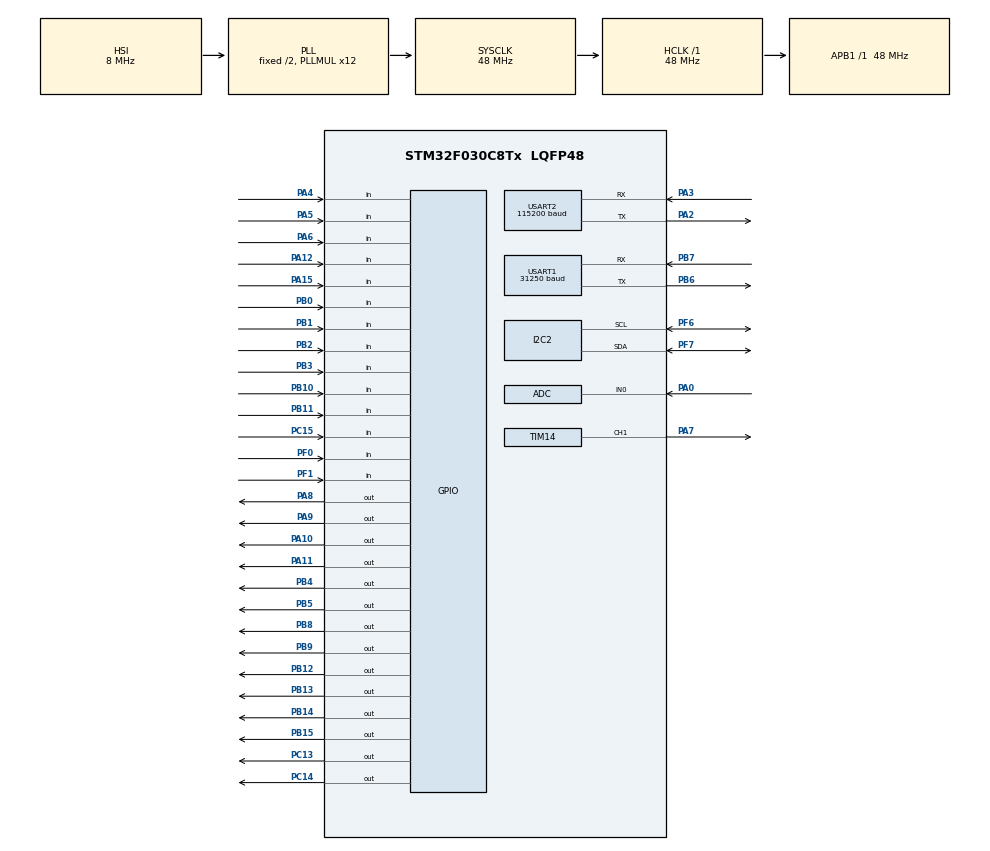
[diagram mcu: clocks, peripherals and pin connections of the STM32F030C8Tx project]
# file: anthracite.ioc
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ADC.SamplingTime=ADC_SAMPLETIME_239CYCLES_5
I2C2.Timing=0x10805D88
Mcu.Family=STM32F0
Mcu.Name=STM32F030C8Tx
Mcu.Package=LQFP48
PA0.Mode=IN0
PA0.Signal=ADC_IN0
PA10.Signal=GPIO_Output
PA11.Signal=GPIO_Output
PA12.Signal=GPIO_Input
PA13.Mode=Serial_Wire
PA13.Signal=SYS_SWDIO
PA14.Mode=Serial_Wire
PA14.Signal=SYS_SWCLK
PA15.GPIO_PuPd=GPIO_PULLUP
PA15.Signal=GPIO_Input
PA2.Mode=Asynchronous
PA2.Signal=USART2_TX
PA3.Mode=Asynchronous
PA3.Signal=USART2_RX
PA4.GPIO_PuPd=GPIO_PULLUP
PA4.Signal=GPIO_Input
PA5.GPIO_PuPd=GPIO_PULLUP
PA5.Signal=GPIO_Input
PA6.GPIO_PuPd=GPIO_PULLUP
PA6.Signal=GPIO_Input
PA7.Signal=S_TIM14_CH1
PA8.Signal=GPIO_Output
PA9.Signal=GPIO_Output
PB0.Signal=GPIO_Input
PB1.Signal=GPIO_Input
PB10.Signal=GPIO_Input
PB11.Signal=GPIO_Input
PB12.Signal=GPIO_Output
PB13.Signal=GPIO_Output
PB14.Signal=GPIO_Output
PB15.Signal=GPIO_Output
PB2.Signal=GPIO_Input
PB3.Signal=GPIO_Input
PB4.Signal=GPIO_Output
PB5.Signal=GPIO_Output
PB6.Mode=Asynchronous
PB6.Signal=USART1_TX
PB7.Mode=Asynchronous
PB7.Signal=USART1_RX
PB8.Signal=GPIO_Output
PB9.Signal=GPIO_Output
PC13.Signal=GPIO_Output
PC14-OSC32_IN.Signal=GPIO_Output
PC15-OSC32_OUT.Signal=GPIO_Input
PF0-OSC_IN.Signal=GPIO_Input
PF1-OSC_OUT.Signal=GPIO_Input
PF6.Mode=I2C
PF6.Signal=I2C2_SCL
PF7.Mode=I2C
PF7.Signal=I2C2_SDA
ProjectManager.HeapSize=0x200
ProjectManager.StackSize=0x400
ProjectManager.TargetToolchain=CMake
RCC.AHBFreq_Value=48000000
RCC.APB1Freq_Value=48000000
RCC.APB1TimFreq_Value=48000000
RCC.HCLKFreq_Value=48000000
RCC.PLLMUL=RCC_PLL_MUL12
RCC.SYSCLKFreq_VALUE=48000000
RCC.SYSCLKSource=RCC_SYSCLKSOURCE_PLLCLK
SH.S_TIM14_CH1.0=TIM14_CH1,PWM Generation1 CH1
TIM14.Channel=TIM_CHANNEL_1
USART1.BaudRate=31250
USART1.VirtualMode-Asynchronous=VM_ASYNC
USART2.BaudRate=115200
USART2.VirtualMode-Asynchronous=VM_ASYNC
VP_ADC_Vref_Input.Mode=IN-Vrefint
VP_TIM14_VS_ClockSourceINT.Mode=Enable_Timer
board=custom

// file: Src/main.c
/* USER CODE BEGIN Header */
/**
  ******************************************************************************
  * @file           : main.c
  * @brief          : Anthracite firmware - main program body
  ******************************************************************************
  * SPDX-FileCopyrightText: 2026 Hayata Yamamoto (Yamamoto Circuit Design)
  * SPDX-License-Identifier: GPL-3.0-or-later
  *
  * Portions generated by STM32CubeMX are
  *   Copyright (c) 2026 STMicroelectronics, licensed under BSD-3-Clause.
  *
  * This program is free software: you can redistribute it and/or modify it
  * under the terms of the GNU General Public License as published by the
  * Free Software Foundation, either version 3 of the License, or (at your
  * option) any later version.
  *
  * This program is distributed in the hope that it will be useful, but
  * WITHOUT ANY WARRANTY; without even the implied warranty of
  * MERCHANTABILITY or FITNESS FOR A PARTICULAR PURPOSE. See the GNU
  * General Public License for more details.
  *
  * You should have received a copy of the GNU General Public License along
  * with this program. If not, see <https://www.gnu.org/licenses/>.
  ******************************************************************************
  */
/* USER CODE END Header */
#include "main.h"

/* USER CODE BEGIN Includes */
#include <stdbool.h>
#include <string.h>
#include <stdio.h>
#include <stdlib.h>
/* USER CODE END Includes */

/* USER CODE BEGIN PTD */
/* VCP debug console: one pin-table row (name lookup, write permission, snapshot output) */
typedef struct {
    GPIO_TypeDef *port;
    uint16_t      pin;
    const char   *name;
    bool          writable;
} dbg_pin_t;
/* USER CODE END PTD */

/* USER CODE BEGIN PD */
/* Firmware version. The boot banner prints it as "anthracite-<FW_VERSION>". Test tools read
   the banner's second word as the firmware ID. The PING reply ("OK PONG v2") is the console protocol
   version and stays independent of this. */
#define FW_VERSION "1.1.0"

/* PL9823-F5 (WS2812-compatible) bit-banged output on PA7.
   PA7 -> R114 -> 74HCT04 (two inverters = non-inverting 5V buffer) -> J105-8 -> top R18 -> D12 DIN */
#define WS_PORT   GPIOA
#define WS_PIN    GPIO_PIN_7
#define WS_HIGH() (WS_PORT->BSRR = WS_PIN)
#define WS_LOW()  (WS_PORT->BSRR = (uint32_t)WS_PIN << 16)
#define NUM_LEDS  1

#define FOOTSW_DEBOUNCE_MS  50
/* Wait after update_mode_pb5() before reading the latch Tip. PB5 (through U107) closes U109 and
   connects the Tip pull-up (+5V -> R127 3k3 -> U109 -> R144 470); the same PB5 also switches U110
   (MIDI-mode Ring source) and D110. Tip must settle before PF0 is sampled. With the on-board C139
   alone the RC is sub-microsecond; with an external cable's capacitance it stays within a few tens
   of microseconds, so 2ms is ample. 2ms also covers a MIDI byte still shifting out of USART1
   (<= 640us with one byte queued) when DIP-SW3 has just gone OFF. */
#define LATCH_PULLUP_SETTLE_MS  2u
/* Latch setting (DIP-SW4 OFF): Tip must hold a new level this long before the effect follows it.
   Measured contact bounce of an external switch on Tip/Ring was about 0.4ms.
   Timing uses the 1ms HAL tick and starts partway through a tick, so the hold actually required
   is 4-5ms. */
#define LATCH_DEBOUNCE_MS       5u
#define IND_SOLID_MS        1000  /* Solid-on time at the start of an indication sequence */
#define IND_BLINK_ON_MS     100
#define IND_BLINK_OFF_MS    100
#define IND_FINAL_OFF_MS    500
#define STARTUP_BLINK_MS    500
#define MIDI_INDICATOR_MS   100   /* PB8/PB9: MIDI activity indicator on-time */
#define LED_FADE_STEP_MS    6     /* PL9823 color fade step interval [ms]; each step closes ~1/3 of the gap */

/* PowerGood ADC (PA0=ADC_IN0) + status LED (PC13)
   Divider R110 10k / R111 3.3k (ratio 3.3/13.3 = 0.24812): 9V in -> 2.23V.
   Warning window: 8.0~12.0V. It encloses the 8.4~11.5V operating range, so the LED does not
   flash inside that range.
   V_DDA is estimated from the VREFINT calibration value to compute the divider voltage [mV];
   PC13 is lit inside the window and blinks at a 0.4s period (50% duty) outside it.
   At 12.0V the divider gives 2.977V, about 0.3V below VDDA (3.28V measured), so the ADC does not saturate. */
#define PGOOD_DIV_LO_MV     1985U  /* Divider voltage for 8.0V (8.0 * 0.24812) */
#define PGOOD_DIV_HI_MV     2977U  /* Divider voltage for 12.0V (12.0 * 0.24812) */
#define PGOOD_POLL_MS       100U   /* ADC sampling interval */
#define PGOOD_BLINK_MS      200U   /* PC13 blink half-period (0.4s period, 50% duty) */
#define ADC_FULL_SCALE      4095U  /* 12bit */
/* VREFINT factory calibration value (taken at VDDA=3.3V). Guarded because bare HAL projects sometimes leave it undefined */
#ifndef VREFINT_CAL_ADDR
#define VREFINT_CAL_ADDR    ((uint16_t *)0x1FFFF7BAU)
#endif
#ifndef VREFINT_CAL_VREF
#define VREFINT_CAL_VREF    3300U    /* mV */
#endif

/* ---- VCP debug console (USART2 PA2/PA3, 115200bps, STLINK-V3 VCP) ---- */
#define DBG_LINE_MAX  64   /* RX line buffer; ample for the longest command ("MSEND"/"MRECV" plus 11 bytes) */
#define DBG_TX_MAX    320  /* TX formatting buffer (a snapshot is ~250 chars, plus the three override fields) */

/* ---- PA8 (Effect) falling-edge delay - pop noise countermeasure ----
   On Effect -> Bypass, PA9 (B-OUT) goes High immediately, but only the PA8 (Effect)
   falling edge is delayed by EFFECT_OFF_DELAY_US. The point is to widen the handover
   overlap between Q8 (bypass side) turning on and Q15 (effect side) turning off
   from 0.6ms to 6.4ms, matching the overlap of the Bypass -> Effect direction.
   Do NOT apply this to the rising edge (Bypass -> Effect): that would shrink the B->E
   overlap from 6.4ms to 0.6ms, making it as hard a splice as E->B, which defeats the purpose.
   Timing uses TIM14 as a 1MHz one-shot (1 count = 1us, max 65.535ms). */
#define EFFECT_OFF_DELAY_US  5800u  /* Default 5.8ms; changeable at runtime with the VCP console EDLY command */
#define EFFECT_OFF_DELAY_MAX 60000u /* Upper bound that still fits the 16-bit TIM14 ARR */

/* MIDI monitor: ring buffer holding USART1 RX/TX bytes tagged with a direction flag.
   Drained by the VCP M command. The size must be a power of two */
#define MIDI_MON_SIZE     128u
#define MIDI_MON_DIR_OUT  0x100u  /* Entry bit8: 0=IN (received), 1=OUT (transmitted) */
#define MIDI_MON_MAX_PER_RESP  40u  /* Max entries per M command (keeps the reply within DBG_TX_MAX) */
/* USER CODE END PD */

ADC_HandleTypeDef hadc;

I2C_HandleTypeDef hi2c2;

TIM_HandleTypeDef htim14;

UART_HandleTypeDef huart1;
UART_HandleTypeDef huart2;

/* USER CODE BEGIN PV */
static bool effect_active = false;

/* PA8 delayed-OFF state. While armed, TIM14 is running and the ISR drives PA8 Low on expiry */
static volatile bool     effect_off_armed    = false;
static volatile uint16_t effect_off_delay_us = EFFECT_OFF_DELAY_US;
static volatile uint16_t effect_off_count    = 0;  /* Number of delayed OFFs executed (reported by EDLY) */

static bool dip_sw1 = false; /* ON(Low)=power-on effect enabled */
static bool dip_sw2 = false; /* ON(Low)=extended bias mode */
static volatile bool dip_sw3 = false; /* ON(Low)=MIDI mode / OFF(High)=latch mode. volatile: the USART1 ISR reads it to gate Thru */
static bool dip_sw4 = false; /* latch mode (OFF) / momentary mode (ON) */

/* Toggle switch inputs (all three have pole = GND and an external +3.3V pull-up).
   Pos1 Low = flipped up / Pos3 Low = flipped down / both High = center.
   The schematic net names match the physical layout. */
static GPIO_PinState prev_latch_tip  = GPIO_PIN_SET; /* PF0 */
static GPIO_PinState prev_latch_ring = GPIO_PIN_SET; /* PF1 */
/* Tip debounce for the latch setting: the level being timed and the HAL tick when it was first seen.
   prev_latch_tip holds the accepted level; latch_tip_cand differs from it while a change is pending. */
static GPIO_PinState latch_tip_cand    = GPIO_PIN_SET;
static uint32_t      latch_tip_cand_ms = 0;
static GPIO_PinState prev_bias_pos1  = GPIO_PIN_SET; /* PB2  */
static GPIO_PinState prev_bias_pos3  = GPIO_PIN_SET; /* PB3  */
static GPIO_PinState prev_resp_pos1  = GPIO_PIN_SET; /* PB0  */
static GPIO_PinState prev_resp_pos3  = GPIO_PIN_SET; /* PB1  */
static GPIO_PinState prev_filt_pos1  = GPIO_PIN_SET; /* PB10 */
static GPIO_PinState prev_filt_pos3  = GPIO_PIN_SET; /* PB11 */
static GPIO_PinState prev_footsw     = GPIO_PIN_SET; /* PA12 */

static volatile uint32_t footsw_debounce_ms = 0;

static uint8_t led_data[NUM_LEDS][3];       /* Current color actually sent to the PL9823 (this is what fades) */
static uint8_t led_target[3] = {0, 0, 0};   /* Target color chosen by update_led(); led_data eases toward it */
static volatile uint32_t led_fade_ms = 0;   /* Countdown to the next fade step (decremented by SysTick) */
static volatile uint8_t led_update_needed = 1;

typedef enum {
    LED_OVERRIDE_NONE = 0,
    LED_OVERRIDE_ORANGE, /* Bias change indication */
    LED_OVERRIDE_GREEN,  /* Input filter change indication */
    LED_OVERRIDE_CYAN,   /* Response change indication */
    LED_OVERRIDE_WHITE,  /* MIDI-Learn store-complete indication */
    LED_OVERRIDE_OFF,    /* forced off (blink gap) */
} led_override_t;
static volatile led_override_t led_override = LED_OVERRIDE_NONE;

typedef enum {
    IND_SEQ_IDLE = 0,
    IND_SEQ_SOLID_1S,
    IND_SEQ_BLINK_OFF,
    IND_SEQ_BLINK_ON,
    IND_SEQ_FINAL_OFF,
} ind_seq_state_t;

typedef struct {
    volatile ind_seq_state_t state;
    volatile uint8_t         blink_remain;
    volatile uint32_t        timer_ms;
    led_override_t           color;
} ind_seq_t;

static ind_seq_t bias_seq   = { IND_SEQ_IDLE, 0, 0, LED_OVERRIDE_ORANGE };
static ind_seq_t filter_seq = { IND_SEQ_IDLE, 0, 0, LED_OVERRIDE_GREEN  };
static ind_seq_t resp_seq   = { IND_SEQ_IDLE, 0, 0, LED_OVERRIDE_CYAN   };
static ind_seq_t learn_seq  = { IND_SEQ_IDLE, 0, 0, LED_OVERRIDE_WHITE  };

static volatile uint32_t startup_blink_ms = 0;
static volatile uint8_t  startup_blink_phase = 0;

/* MIDI IN (USART1, 31250bps) - parses Control Change messages.
   DIP-SW4 OFF: fixed trigger CH12 CC81 / DIP-SW4 ON: the CH/CC stored by MIDI-Learn */
#define TRIG_CH_FIXED  11u    /* CH12 (0-indexed) */
#define TRIG_CC_FIXED  0x51u  /* CC81 */
/* CCs that change the toggle settings over MIDI.
   The channel follows the same rule as on/off control (DIP-SW4 OFF = fixed CH12 / ON = the MIDI-Learn channel).
   value 0 means "revert": clear the MIDI override and follow the physical toggle again.
   value 1-127 is split into four bands (1-31/32-63/64-95/96-127) to select the state. */
#define TOGGLE_CC_INPUT     83u  /* 0=revert / Single / Hum / Wah / All-OFF */
#define TOGGLE_CC_RESPONSE  84u  /* 0=revert / Steep / Medium / Gradual / (N/A) */
#define TOGGLE_CC_BIAS      85u  /* 0=revert / Center / Offset / Skew / X-Skew */
typedef enum { MIDI_IDLE = 0, MIDI_DATA1, MIDI_DATA2 } midi_state_t;
static volatile uint8_t   midi_rx_buf  = 0;
static          midi_state_t midi_state = MIDI_IDLE;
static          uint8_t      midi_status = 0; /* Most recent Channel Voice status byte */
static          uint8_t      midi_cc_num = 0;
/* Received-CC event queue (SPSC: the ISR produces, poll_midi consumes).
   A single-event slot drops CCs that arrive back to back, as in a preset recall, because the
   next one overwrites it before poll_midi runs. A ring buffer serializes them (size = power of two).
   Push only from the USART1 ISR or inside an __disable_irq() section (MRECV injection). */
#define MIDI_EVT_SIZE 16u
typedef struct { uint8_t ch, cc, val; } midi_evt_t;
static volatile midi_evt_t midi_evt_buf[MIDI_EVT_SIZE];
static volatile uint8_t    midi_evt_head = 0;
static volatile uint8_t    midi_evt_tail = 0;

/* MIDI receive health counters (read and cleared with the VCP MSTAT command).
   Observation points added to prove numerically that a burst of CCs loses nothing.
   - midi_rx_err  : USART1 receive errors (ORE/FE/NE) = a proxy for bytes lost on the wire
   - midi_evt_drop: CCs dropped because the event queue was full (proof that poll_midi fell behind)
   - midi_evt_qmax: high-water mark of queue usage (measured headroom against 16)
   - midi_cc_rx   : total CCs that reached midi_process_event() (cross-check against the host)
   All are plain increments without saturation, but uint16 is plenty in practice (CLR before a test). */
static volatile uint16_t midi_rx_err   = 0;
static volatile uint16_t midi_evt_drop = 0;
static volatile uint8_t  midi_evt_qmax = 0;
static volatile uint16_t midi_cc_rx    = 0;

/* MIDI override state for the toggle settings.
   Moving a physical toggle clears the override and returns to reading the switch (done in poll_*_switch).
   While override != NONE, update_*_output() applies it in preference to the physical reading. */
typedef enum {
    FILT_OVR_NONE = 0,   /* follow the physical toggle */
    FILT_OVR_SINGLE, FILT_OVR_HUM, FILT_OVR_WAH, FILT_OVR_ALLOFF,
} filt_ovr_t;
typedef enum {
    RESP_OVR_NONE = 0,
    RESP_OVR_STEEP, RESP_OVR_MEDIUM, RESP_OVR_GRADUAL,
} resp_ovr_t;
typedef enum {
    BIAS_OVR_NONE = 0,
    BIAS_OVR_CENTER, BIAS_OVR_OFFSET, BIAS_OVR_SKEW, BIAS_OVR_XSKEW,
} bias_ovr_t;
static volatile filt_ovr_t filter_override   = FILT_OVR_NONE;
static volatile resp_ovr_t response_override = RESP_OVR_NONE;
static volatile bias_ovr_t bias_override     = BIAS_OVR_NONE;
static volatile uint32_t  midi_indicator_ms     = 0; /* PB8 (MIDI-IN RX) ON time */
static volatile uint32_t  midi_out_indicator_ms = 0; /* PB9 (MIDI-OUT TX) ON time */

/* Periodic MIDI-OUT Active Sensing (0xFE) as a link keep-alive.
   Per the MIDI spec a receiver declares the link dead after 300ms of silence following a 0xFE,
   so send every 250ms for margin. Sent only in MIDI mode (DIP-SW3 ON). MIDI-OUT and the latch input
   share the J104 Tip (PB6 -> R123 -> U107 1->2->3->4 -> D118 -> R128 -> Tip), and no hardware gate
   cuts the driver in latch mode, so any USART1 byte sent then would pull Tip Low and PF0 would read
   it as a footswitch press. The firmware therefore keeps USART1 TX silent in latch mode. */
#define MIDI_AS_INTERVAL_MS 250u
static volatile uint32_t  midi_as_timer_ms = MIDI_AS_INTERVAL_MS;
static volatile bool      midi_as_pending  = false;

/* Do not send our own Active Sensing while Thru traffic is flowing.
   poll_midi_out_sensing() writes 0xFE as soon as TXE is free, so unconditionally it would land
   in the middle of a Thru message (between the 2nd and 3rd byte of a CC, say). The MIDI spec
   allows System Real-Time bytes anywhere and obliges receivers to pass them through, but
   **some receivers really do drop such a sequence** (observed with CH34x-based USB-MIDI
   interfaces). To avoid losses downstream, hold our 0xFE back while Thru has just been active.

   Why this is safe: the Active Sensing timeout (300ms) means "declare the link dead if no MIDI
   data at all arrives within 300ms of a 0xFE". While Thru is passing data the downstream timer
   keeps being reset, so suppressing our own 0xFE cannot cause a false disconnect. Upstream 0xFE
   is passed through by Thru as well, so whatever the upstream sends still reaches the downstream.

   THRU_IDLE_GUARD_MS is set well above the inter-byte gap within a message (320us at 31250bps).
   5ms exceeds a whole 3-byte message (960us) and still leaves room for jitter. */
#define THRU_IDLE_GUARD_MS 5u
static volatile uint32_t  thru_idle_ms   = 0;  /* Guard time remaining since the last Thru byte [ms] */
static volatile uint16_t  midi_as_tx     = 0;  /* Number of 0xFE actually transmitted (MSTAT) */
static volatile uint16_t  midi_as_hold   = 0;  /* Number of 0xFE delayed by the guard (MSTAT) */
static volatile bool      midi_as_held   = false; /* Whether the current pending 0xFE is already counted */

/* MIDI-Learn (PC15 button + M24C64 EEPROM) */
#define EEPROM_I2C_ADDR  0xA0u   /* M24C64 (E2/E1/E0=GND). WP=GND, so writes are enabled */
#define EEPROM_MEM_ADDR  0x0000u
#define LEARN_MAGIC      0xA5u
#define LEARN_TIMEOUT_MS 10000u  /* Auto-cancel of the learn-armed state */
#define LEARN_BLINK_MS   250u    /* White blink half-period while learn-armed */
#define PC15_DEBOUNCE_MS 50u
static volatile bool      learn_armed   = false; /* learn mode armed */
static volatile bool      learn_valid   = false; /* a valid learned value is stored */
static volatile uint8_t   learn_ch      = 0;     /* 0..15 */
static volatile uint8_t   learn_cc      = 0;     /* 0..127 */
static volatile bool      learn_save_request = false; /* ISR -> main loop: EEPROM write request */
static volatile uint32_t  learn_timeout_ms = 0;
static volatile uint32_t  learn_blink_ms   = 0;
static volatile uint8_t   learn_blink_phase = 0;
static volatile uint32_t  pc15_debounce_ms = 0;
static GPIO_PinState      prev_pc15 = GPIO_PIN_SET;

/* PowerGood (PA0 ADC / PC13 status LED) */
static volatile bool      power_good        = false; /* true = inside the window */
static volatile uint32_t  pgood_poll_ms     = 0;     /* Countdown to the next measurement */
static volatile uint32_t  pgood_blink_ms    = 0;     /* PC13 blink half-period counter */
static volatile uint8_t   pgood_blink_phase = 0;
/* PowerGood simulation override (for testing): 0=AUTO (measured) / 1=force good / 2=force bad.
   A VCP debug feature (PGSIM command) for checking the main LED PG blink without varying the supply. */
static volatile uint8_t   pg_sim            = 0;

/* Latest PowerGood measurements (for the S and ADC debug replies) */
static volatile uint16_t  pgood_pa0_raw  = 0;
static volatile uint16_t  pgood_vref_raw = 0;
static volatile uint32_t  pgood_vdda_mv  = 0;
static volatile uint32_t  pgood_vpa0_mv  = 0;

/* ---- VCP debug console (USART2) state ---- */
static volatile bool    dbg_active        = false; /* true: normal control stopped, GPIO/LED driven externally */
static volatile char    dbg_line[DBG_LINE_MAX];    /* RX line buffer filled by the ISR */
static volatile uint8_t dbg_line_len      = 0;
static volatile bool    dbg_line_ready    = false; /* Line complete; the ISR leaves it alone until the main loop is done */
static volatile bool    dbg_line_overflow = false;
static char             dbg_tx_buf[DBG_TX_MAX];    /* TX formatting buffer, main loop only */

/* Debug pins: 14 outputs + 14 inputs. Snapshots are printed in this order */
static const dbg_pin_t dbg_pins[] = {
    { GPIOA, GPIO_PIN_8,  "PA8",  true  },  /* /E1 effect in/out */
    { GPIOA, GPIO_PIN_9,  "PA9",  true  },  /* /B1 bypass out */
    { GPIOA, GPIO_PIN_10, "PA10", true  },  /* /A1 Bias 1.5 */
    { GPIOA, GPIO_PIN_11, "PA11", true  },  /* /A2 Bias 3.0 */
    { GPIOB, GPIO_PIN_4,  "PB4",  true  },  /* /R1 Response Medium */
    { GPIOB, GPIO_PIN_12, "PB12", true  },  /* /F1 Filter Single */
    { GPIOB, GPIO_PIN_13, "PB13", true  },  /* /F2 Filter Hum */
    { GPIOB, GPIO_PIN_14, "PB14", true  },  /* /F3 Filter Wah */
    { GPIOB, GPIO_PIN_15, "PB15", true  },  /* /R2 Response Gradual */
    { GPIOB, GPIO_PIN_5,  "PB5",  true  },  /* Latch/MIDI mode: H = Tip pull-up (U109) + D110, L = Ring source (U110) */
    { GPIOB, GPIO_PIN_8,  "PB8",  true  },  /* MIDI-IN activity LED */
    { GPIOB, GPIO_PIN_9,  "PB9",  true  },  /* MIDI-OUT activity LED */
    { GPIOC, GPIO_PIN_13, "PC13", true  },  /* PowerGood status LED */
    { GPIOC, GPIO_PIN_14, "PC14", true  },  /* Heartbeat LED */
    { GPIOA, GPIO_PIN_4,  "PA4",  false },  /* DIP-SW1 */
    { GPIOA, GPIO_PIN_5,  "PA5",  false },  /* DIP-SW2 */
    { GPIOA, GPIO_PIN_6,  "PA6",  false },  /* DIP-SW3 */
    { GPIOA, GPIO_PIN_15, "PA15", false },  /* DIP-SW4 */
    { GPIOA, GPIO_PIN_12, "PA12", false },  /* Footswitch */
    { GPIOB, GPIO_PIN_0,  "PB0",  false },  /* Response Pos1 */
    { GPIOB, GPIO_PIN_1,  "PB1",  false },  /* Response Pos3 */
    { GPIOB, GPIO_PIN_2,  "PB2",  false },  /* Bias Pos1 */
    { GPIOB, GPIO_PIN_3,  "PB3",  false },  /* Bias Pos3 */
    { GPIOB, GPIO_PIN_10, "PB10", false },  /* Filter Pos1 */
    { GPIOB, GPIO_PIN_11, "PB11", false },  /* Filter Pos3 */
    { GPIOC, GPIO_PIN_15, "PC15", false },  /* MIDI-Learn button */
    { GPIOF, GPIO_PIN_0,  "PF0",  false },  /* Latch Tip */
    { GPIOF, GPIO_PIN_1,  "PF1",  false },  /* Latch Ring */
};
#define DBG_NUM_PINS (sizeof(dbg_pins) / sizeof(dbg_pins[0]))

/* MIDI monitor ring buffer. Push only from the USART1 ISR or inside an __disable_irq()
   section (= a serialized producer). Only the main loop (M command) advances the tail */
static volatile uint16_t midi_mon_buf[MIDI_MON_SIZE];
static volatile uint8_t  midi_mon_head  = 0;
static volatile uint8_t  midi_mon_tail  = 0;
static volatile uint16_t midi_mon_drops = 0;  /* Bytes dropped because the buffer was full */
/* USER CODE END PV */

void SystemClock_Config(void);
static void MX_GPIO_Init(void);
static void MX_I2C2_Init(void);
static void MX_TIM14_Init(void);
static void MX_USART1_UART_Init(void);
static void MX_USART2_UART_Init(void);
static void MX_ADC_Init(void);
/* USER CODE BEGIN PFP */
static void ws_send_byte(uint8_t byte);
static void ws_send(void);
static void poll_led_fade(void);
static void update_signal_path(void);
static void effect_off_schedule(void);
static void effect_off_cancel(void);
static void update_bias_output(void);
static void update_response_output(void);
static void update_filter_output(void);
static void update_led(void);
static void poll_footswitch(void);
static void poll_latch_input(void);
static void latch_snapshot(void);
static uint8_t get_bias_blink_count(GPIO_PinState pos1, GPIO_PinState pos3);
static uint8_t get_response_blink_count(GPIO_PinState pos1, GPIO_PinState pos3);
static uint8_t get_filter_blink_count(GPIO_PinState pos1, GPIO_PinState pos3);
static void ind_seq_start(ind_seq_t *seq, uint8_t blinks);
static void ind_seq_cancel_others(const ind_seq_t *keep);
static void ind_seq_tick(ind_seq_t *seq, bool active);
static void poll_bias_switch(void);
static void poll_response_switch(void);
static void poll_filter_switch(void);
static void poll_midi(void);
static void midi_evt_push(uint8_t ch, uint8_t cc, uint8_t val);
static void midi_parse_byte(uint8_t b);
static void midi_process_event(uint8_t ch, uint8_t cc, uint8_t val);
static void apply_midi_input(uint8_t val);
static void apply_midi_response(uint8_t val);
static void apply_midi_bias(uint8_t val);
static void midi_inject_rx_byte(uint8_t b);
static void poll_midi_out_sensing(void);
static void poll_midi_learn(void);
static void update_mode_pb5(void);
static bool eeprom_save_learn(void);
static void eeprom_load_learn(void);
static void midi_handle_cc(uint8_t ch, uint8_t cc, uint8_t val);
static void thru_send_byte(uint8_t b);
static void midi_thru_filter(uint8_t b);
static uint16_t adc_read_ch(uint32_t chselr_bit);
static void poll_power_good(void);
static void measure_power_good(void);
static void dbg_send_str(const char *s);
static void poll_debug_uart(void);
static void dbg_exit(void);
static void midi_mon_push(uint16_t dir_flag, uint8_t b);
static void midi_inject_byte(uint8_t b);
/* USER CODE END PFP */

/* USER CODE BEGIN 0 */

/* ---- PL9823-F5 / WS2812 bit-banging (PA7) ----
   NOP counts tuned for 48MHz Cortex-M0 (ported from an STM32C0 @ 48MHz).
   Targets: T0H 0.35us / T0L 0.9us / T1H 0.7us / T1L 0.55us, RGB order */
static void ws_send_byte(uint8_t byte)
{
    for (int i = 7; i >= 0; i--) {
        if (byte & (1 << i)) {
            WS_HIGH();
            __NOP();__NOP();__NOP();__NOP();__NOP();
            __NOP();__NOP();__NOP();__NOP();__NOP();
            __NOP();__NOP();__NOP();__NOP();__NOP();
            __NOP();__NOP();__NOP();__NOP();__NOP();
            __NOP();__NOP();__NOP();__NOP();__NOP();
            __NOP();__NOP();
            WS_LOW();
            __NOP();__NOP();__NOP();__NOP();__NOP();
            __NOP();__NOP();__NOP();__NOP();__NOP();
            __NOP();__NOP();__NOP();__NOP();__NOP();
            __NOP();__NOP();__NOP();__NOP();
        } else {
            WS_HIGH();
            __NOP();__NOP();__NOP();__NOP();__NOP();
            __NOP();__NOP();__NOP();__NOP();__NOP();
            WS_LOW();
            __NOP();__NOP();__NOP();__NOP();__NOP();
            __NOP();__NOP();__NOP();__NOP();__NOP();
            __NOP();__NOP();__NOP();__NOP();__NOP();
            __NOP();__NOP();__NOP();__NOP();__NOP();
            __NOP();__NOP();__NOP();__NOP();__NOP();
            __NOP();__NOP();__NOP();__NOP();__NOP();
            __NOP();__NOP();__NOP();__NOP();__NOP();
            __NOP();
        }
    }
}

static void ws_send(void)
{
    __disable_irq();
    for (int i = 0; i < NUM_LEDS; i++) {
        ws_send_byte(led_data[i][0]); /* R */
        ws_send_byte(led_data[i][1]); /* G */
        ws_send_byte(led_data[i][2]); /* B */
    }
    __enable_irq();
    HAL_Delay(1); /* reset >50us */
}

/* Input filter, 3 states (Single/Hum/Wah)
   Inputs PB10(Pos1)/PB11(Pos3) -> outputs PB12(Single)/PB13(Hum)/PB14(Wah)
   Flipped up (Pos1=L) = Wah / center = Hum / flipped down (Pos3=L) = Single
   All three go Low when bypassed, disconnecting the input stage.
   An active MIDI override wins over the physical toggle and can also select All-OFF (all three Low). */
static void update_filter_output(void)
{
    if (!effect_active) {
        HAL_GPIO_WritePin(GPIOB, GPIO_PIN_12, GPIO_PIN_RESET);
        HAL_GPIO_WritePin(GPIOB, GPIO_PIN_13, GPIO_PIN_RESET);
        HAL_GPIO_WritePin(GPIOB, GPIO_PIN_14, GPIO_PIN_RESET);
        return;
    }
    GPIO_PinState single = GPIO_PIN_RESET, hum = GPIO_PIN_RESET, wah = GPIO_PIN_RESET;

    if (filter_override != FILT_OVR_NONE) {
        switch (filter_override) {
            case FILT_OVR_SINGLE: single = GPIO_PIN_SET; break;
            case FILT_OVR_HUM:    hum    = GPIO_PIN_SET; break;
            case FILT_OVR_WAH:    wah    = GPIO_PIN_SET; break;
            case FILT_OVR_ALLOFF: /* all three Low */      break;
            default: break;
        }
    } else {
        GPIO_PinState pos1 = HAL_GPIO_ReadPin(GPIOB, GPIO_PIN_10);
        GPIO_PinState pos3 = HAL_GPIO_ReadPin(GPIOB, GPIO_PIN_11);
        if (pos1 == GPIO_PIN_RESET && pos3 == GPIO_PIN_SET) {
            wah = GPIO_PIN_SET;     /* flipped up */
        } else if (pos1 == GPIO_PIN_SET && pos3 == GPIO_PIN_RESET) {
            single = GPIO_PIN_SET;  /* flipped down */
        } else {
            hum = GPIO_PIN_SET;     /* center */
        }
    }
    HAL_GPIO_WritePin(GPIOB, GPIO_PIN_12, single);
    HAL_GPIO_WritePin(GPIOB, GPIO_PIN_13, hum);
    HAL_GPIO_WritePin(GPIOB, GPIO_PIN_14, wah);
}

/* Bias, 3 states: inputs PB2(Pos1)/PB3(Pos3) -> outputs PA10(BIAS15)/PA11(BIAS30)
   Standard mode (DIP-SW2 OFF): up=3:1 (Skew) / center=2:1 (Offset) / down=1:1 (Center)
   Extended mode (DIP-SW2 ON) : up=4:1 (X-Skew) / center=3:1 (Skew) / down=2:1 (Offset)
   Both outputs Low is the default Center (1:1). This switches inside the fuzz circuit, so it stays
   driven even when bypassed, to avoid a switching transient at the moment the effect is engaged. */
static void update_bias_output(void)
{
    GPIO_PinState bias15, bias30;

    if (bias_override != BIAS_OVR_NONE) {
        /* A MIDI override drives the output pins directly, ignoring DIP-SW2 extended mode.
           Center=00 / Offset=10 / Skew=01 / X-Skew=11 (PA10,PA11).
           X-Skew (both High) is the 4:1 setting, the same state as extended mode (DIP-SW2 ON) with the
           toggle up, so it is reachable both over MIDI and from the panel. */
        switch (bias_override) {
            case BIAS_OVR_CENTER: bias15 = GPIO_PIN_RESET; bias30 = GPIO_PIN_RESET; break;
            case BIAS_OVR_OFFSET: bias15 = GPIO_PIN_SET;   bias30 = GPIO_PIN_RESET; break;
            case BIAS_OVR_SKEW:   bias15 = GPIO_PIN_RESET; bias30 = GPIO_PIN_SET;   break;
            case BIAS_OVR_XSKEW:  bias15 = GPIO_PIN_SET;   bias30 = GPIO_PIN_SET;   break;
            default:              bias15 = GPIO_PIN_RESET; bias30 = GPIO_PIN_RESET; break;
        }
    } else {
        GPIO_PinState pos1 = HAL_GPIO_ReadPin(GPIOB, GPIO_PIN_2);
        GPIO_PinState pos3 = HAL_GPIO_ReadPin(GPIOB, GPIO_PIN_3);
        if (dip_sw2) {
            if (pos1 == GPIO_PIN_RESET && pos3 == GPIO_PIN_SET) {
                bias15 = GPIO_PIN_SET;   bias30 = GPIO_PIN_SET;   /* up: 4:1 */
            } else if (pos1 == GPIO_PIN_SET && pos3 == GPIO_PIN_RESET) {
                bias15 = GPIO_PIN_SET;   bias30 = GPIO_PIN_RESET; /* down: 2:1 */
            } else {
                bias15 = GPIO_PIN_RESET; bias30 = GPIO_PIN_SET;   /* center: 3:1 */
            }
        } else {
            if (pos1 == GPIO_PIN_RESET && pos3 == GPIO_PIN_SET) {
                bias15 = GPIO_PIN_RESET; bias30 = GPIO_PIN_SET;   /* up: 3:1 */
            } else if (pos1 == GPIO_PIN_SET && pos3 == GPIO_PIN_RESET) {
                bias15 = GPIO_PIN_RESET; bias30 = GPIO_PIN_RESET; /* down: 1:1 */
            } else {
                bias15 = GPIO_PIN_SET;   bias30 = GPIO_PIN_RESET; /* center: 2:1 */
            }
        }
    }
    HAL_GPIO_WritePin(GPIOA, GPIO_PIN_10, bias15);
    HAL_GPIO_WritePin(GPIOA, GPIO_PIN_11, bias30);
}

/* Response, 3 states (Steep/Medium/Gradual)
   Inputs PB0(Pos1)/PB1(Pos3) -> outputs PB4(Medium)/PB15(Gradual)
   Flipped up (Pos1=L) = Gradual / center = Medium / flipped down (Pos3=L) = Steep
   Steep is the default state with both outputs Low (R4, the series resistor in the fuzz input stage, at maximum).
   Like Bias, this stays driven even when bypassed. */
static void update_response_output(void)
{
    GPIO_PinState medium = GPIO_PIN_RESET, gradual = GPIO_PIN_RESET;

    if (response_override != RESP_OVR_NONE) {
        if (response_override == RESP_OVR_MEDIUM)       medium  = GPIO_PIN_SET;
        else if (response_override == RESP_OVR_GRADUAL) gradual = GPIO_PIN_SET;
        /* RESP_OVR_STEEP: both outputs off */
    } else {
        GPIO_PinState pos1 = HAL_GPIO_ReadPin(GPIOB, GPIO_PIN_0);
        GPIO_PinState pos3 = HAL_GPIO_ReadPin(GPIOB, GPIO_PIN_1);
        if (pos1 == GPIO_PIN_RESET && pos3 == GPIO_PIN_SET) {
            gradual = GPIO_PIN_SET;  /* flipped up */
        } else if (pos1 == GPIO_PIN_SET && pos3 == GPIO_PIN_RESET) {
            /* flipped down: Steep - both outputs off */
        } else {
            medium = GPIO_PIN_SET;   /* center */
        }
    }
    HAL_GPIO_WritePin(GPIOB, GPIO_PIN_4,  medium);
    HAL_GPIO_WritePin(GPIOB, GPIO_PIN_15, gradual);
}

/* Schedule the PA8 Low transition effect_off_delay_us from now (TIM14 one-shot).
   If one is already armed, keep the current expiry instead of restarting it.
   With a delay of 0 the timer is skipped and PA8 goes Low at once (EDLY 0 restores the old behavior). */
static void effect_off_schedule(void)
{
    if (effect_off_delay_us == 0u) {
        effect_off_cancel();
        HAL_GPIO_WritePin(GPIOA, GPIO_PIN_8, GPIO_PIN_RESET);
        return;
    }
    if (effect_off_armed) return;

    TIM14->CR1  &= ~TIM_CR1_CEN;
    TIM14->ARR   = (uint16_t)(effect_off_delay_us - 1u);  /* PSC=47 -> 1 count = 1us */
    TIM14->CNT   = 0;
    TIM14->EGR   = TIM_EGR_UG;      /* Load ARR immediately (this also sets UIF) */
    TIM14->SR    = 0;               /* Clear the UIF raised by UG before enabling the interrupt */
    effect_off_armed = true;
    TIM14->DIER |= TIM_DIER_UIE;
    TIM14->CR1  |= TIM_CR1_CEN;
}

/* Cancel a pending PA8 delayed-OFF. The caller decides what state PA8 ends up in */
static void effect_off_cancel(void)
{
    TIM14->CR1  &= ~TIM_CR1_CEN;
    TIM14->DIER &= ~TIM_DIER_UIE;
    TIM14->SR    = 0;
    effect_off_armed = false;
}

/* TIM14 expiry = execute the delayed OFF. It is a one-shot, so stop the counter here
   (TIM14 CR1 has no OPM bit, so it will not stop by itself) */
void TIM14_IRQHandler(void)
{
    if (TIM14->SR & TIM_SR_UIF) {
        TIM14->SR   = (uint16_t)~TIM_SR_UIF;
        TIM14->CR1 &= ~TIM_CR1_CEN;
        TIM14->DIER &= ~TIM_DIER_UIE;
        if (effect_off_armed) {
            HAL_GPIO_WritePin(GPIOA, GPIO_PIN_8, GPIO_PIN_RESET);
            effect_off_armed = false;
            effect_off_count++;
        }
    }
}

/* Signal path: PA8 (effect in/out) / PA9 (bypass out). Also refreshes Bias, Response and Filter.
   On Effect -> Bypass only the PA8 falling edge is delayed by effect_off_delay_us
   (PA9 is immediate). The other direction stays immediate on both. See the EFFECT_OFF_DELAY_US notes */
static void update_signal_path(void)
{
    if (effect_active) {
        effect_off_cancel();  /* Cancel if the effect is re-engaged while a delayed OFF is pending */
        HAL_GPIO_WritePin(GPIOA, GPIO_PIN_8, GPIO_PIN_SET);   /* effect in/out */
        HAL_GPIO_WritePin(GPIOA, GPIO_PIN_9, GPIO_PIN_RESET); /* bypass off */
    } else {
        HAL_GPIO_WritePin(GPIOA, GPIO_PIN_9, GPIO_PIN_SET);   /* bypass on: immediate */
        if (HAL_GPIO_ReadPin(GPIOA, GPIO_PIN_8) == GPIO_PIN_SET) {
            effect_off_schedule();     /* delay the falling edge only */
        } else {
            HAL_GPIO_WritePin(GPIOA, GPIO_PIN_8, GPIO_PIN_RESET); /* already Low: just confirm it */
        }
    }
    update_bias_output();
    update_response_output();
    update_filter_output();
}

/* PL9823 indicator color palette {R,G,B}, gathered here by purpose so it is easy to tune
   (the PL9823 takes R,G,B in that order - see ws_send). All-255 white looks yellowish, so use a corrected white. */
static const uint8_t LED_RED[3]        = {255,  12,   0}; /* effect on (default) */
static const uint8_t LED_ORANGE[3]     = {255,  72,   0}; /* Bias change indication */
static const uint8_t LED_GREEN[3]      = { 78, 227,  24}; /* Input filter change indication */
static const uint8_t LED_CYAN[3]       = {  0, 137, 153}; /* Response change indication */
static const uint8_t LED_WHITE[3]      = {169, 145, 255}; /* MIDI-Learn armed (blinking) / store complete */
static const uint8_t LED_MIDI_OVR[3]   = {161,   0, 167}; /* MIDI override active (state differs from the toggles) */
static const uint8_t LED_MIDI_XSKEW[3] = {255,   0,  74}; /* same, but the exception color for Bias=X-Skew */
static const uint8_t LED_PG_BLUE[3]    = { 30,  10, 237}; /* PowerGood out of range, effect on: alternates with red */
static const uint8_t LED_PG_DIMRED[3]  = {  2,   0,   0}; /* PowerGood out of range, effect off: alternates with dark */

static void update_led(void)
{
    const uint8_t *c = NULL;  /* Selected color; NULL = off */

    /* MIDI-Learn armed has top priority: white blink */
    if (learn_armed) {
        if (learn_blink_phase) c = LED_WHITE;
    } else if (led_override == LED_OVERRIDE_ORANGE) {
        c = LED_ORANGE;
    } else if (led_override == LED_OVERRIDE_GREEN) {
        c = LED_GREEN;
    } else if (led_override == LED_OVERRIDE_CYAN) {
        c = LED_CYAN;
    } else if (led_override == LED_OVERRIDE_WHITE) {
        c = LED_WHITE;
    } else if (led_override == LED_OVERRIDE_OFF) {
        /* forced off - c stays NULL */
    } else if (!power_good) {
        /* Warn on the main LED too when PowerGood is out of range (supply outside 8.0-12.0V).
           The blink phase is pgood_blink_phase, shared with PC13 (SysTick drives a 200ms half-period).
           Effect on: red(255,12,0) <-> blue(30,10,237) / effect off: dim red(2,0,0) <-> dark.
           Lower priority than the indication sequences and MIDI-Learn, higher than the steady colors (red/purple/pink/off). */
        if (effect_active) {
            c = pgood_blink_phase ? LED_RED : LED_PG_BLUE;
        } else {
            c = pgood_blink_phase ? LED_PG_DIMRED : NULL;
        }
    } else if (effect_active) {
        /* While a MIDI CC overrides Input, Response or Bias, light a dedicated color instead of
           the default red to show that the actual state does not match the physical toggles.
           Bias=X-Skew is the exception and gets a color of its own. */
        if (filter_override   != FILT_OVR_NONE ||
            response_override != RESP_OVR_NONE ||
            bias_override     != BIAS_OVR_NONE) {
            c = (bias_override == BIAS_OVR_XSKEW) ? LED_MIDI_XSKEW : LED_MIDI_OVR;
        } else {
            c = LED_RED;
        }
    }

    /* Only update the target color; poll_led_fade() eases led_data toward it and does the sending. */
    if (c) {
        led_target[0] = c[0];
        led_target[1] = c[1];
        led_target[2] = c[2];
    } else {
        led_target[0] = 0;
        led_target[1] = 0;
        led_target[2] = 0;
    }
}

/* Move one channel one step toward the target: about 1/3 of the remaining gap (ease-out),
   with a minimum of +/-1 so it always converges. Returns true if the value changed. */
static bool led_fade_step_channel(uint8_t *cur, uint8_t target)
{
    int diff = (int)target - (int)*cur;
    if (diff == 0) return false;
    int move = diff / 3;                          /* about 1/3 of the gap (ease-out) */
    if (move == 0) move = (diff > 0) ? 1 : -1;    /* close the remainder at +/-1 per step */
    *cur = (uint8_t)((int)*cur + move);
    return true;
}

/* Called on every main-loop pass: ease led_data toward led_target and ws_send if anything changed.
   One step per LED_FADE_STEP_MS, timed by led_fade_ms in SysTick.
   Once the target is reached it returns without sending, so idling costs nothing. */
static void poll_led_fade(void)
{
    if (led_fade_ms != 0) return;                 /* wait for the next step */
    bool changed = false;
    if (led_fade_step_channel(&led_data[0][0], led_target[0])) changed = true;
    if (led_fade_step_channel(&led_data[0][1], led_target[1])) changed = true;
    if (led_fade_step_channel(&led_data[0][2], led_target[2])) changed = true;
    if (changed) {
        ws_send();
        led_fade_ms = LED_FADE_STEP_MS;
    }
}

static void poll_footswitch(void)
{
    if (footsw_debounce_ms > 0) return;
    GPIO_PinState cur = HAL_GPIO_ReadPin(GPIOA, GPIO_PIN_12);
    if (cur != prev_footsw) {
        prev_footsw = cur;
        if (cur == GPIO_PIN_RESET) {
            effect_active = !effect_active;
            update_signal_path();
            led_update_needed = 1;
        }
        footsw_debounce_ms = FOOTSW_DEBOUNCE_MS;
    }
}

/* Re-read Tip/Ring as the accepted levels and restart the Tip debounce from them.
   Used wherever the latch inputs are re-snapshotted: power-on, DIP-SW3/SW4 change and DBG OFF. */
static void latch_snapshot(void)
{
    prev_latch_tip    = HAL_GPIO_ReadPin(GPIOF, GPIO_PIN_0);
    prev_latch_ring   = HAL_GPIO_ReadPin(GPIOF, GPIO_PIN_1);
    latch_tip_cand    = prev_latch_tip;
    latch_tip_cand_ms = HAL_GetTick();
}

/* Latch inputs PF0(Tip)/PF1(Ring). Active only in latch mode (DIP-SW3 OFF).
   DIP-SW4 selects how they behave:
     SW4 ON(Low)  = momentary: Tip H->L turns on, Ring H->L turns off (L->H is ignored)
     SW4 OFF(High)= latch    : follows the Tip level (L=on / H=off). Ring is unused.
   Note: Ring serves only as the off input in momentary operation, as the manual documents it.
     update_led() picks the LED color from the effect state and leaves prev_latch_ring unread.
   Note: prev_latch_* is re-snapshotted the moment DIP-SW4 changes, to avoid a false trigger, so
     switching mode with Tip held closed does not take effect until Tip next moves.
   Latch setting debounce: a new Tip level is accepted only after it has held for LATCH_DEBOUNCE_MS,
     so contact bounce no longer toggles the signal path several times. Momentary operation keeps
     its set/reset scheme (an H->L edge on Tip sets, on Ring resets), which bounce cannot upset. */
static void poll_latch_input(void)
{
    if (dip_sw3) return; /* MIDI mode: latch input disabled */

    GPIO_PinState tip  = HAL_GPIO_ReadPin(GPIOF, GPIO_PIN_0);
    GPIO_PinState ring = HAL_GPIO_ReadPin(GPIOF, GPIO_PIN_1);

    if (dip_sw4) {
        /* Momentary: react to the down edge (H->L) only */
        if (tip != prev_latch_tip) {
            prev_latch_tip = tip;
            if (tip == GPIO_PIN_RESET && !effect_active) { /* H->L: on */
                effect_active = true;
                update_signal_path();
                led_update_needed = 1;
            }
        }
        if (ring != prev_latch_ring) {
            prev_latch_ring = ring;
            if (ring == GPIO_PIN_RESET && effect_active) { /* H->L: off */
                effect_active = false;
                update_signal_path();
                led_update_needed = 1;
            }
        }
    } else {
        /* Latch: follows the debounced Tip level. Ring switches nothing here: a Ring change only
           sets led_update_needed below, and update_led() takes the color from the effect state
           without reading Ring (see above), so the LED keeps its color. */
        uint32_t now = HAL_GetTick();
        if (tip != latch_tip_cand) {
            latch_tip_cand    = tip;          /* level moved: restart the timer */
            latch_tip_cand_ms = now;
        } else if (tip != prev_latch_tip &&
                   (uint32_t)(now - latch_tip_cand_ms) >= LATCH_DEBOUNCE_MS) {
            prev_latch_tip = tip;             /* held long enough: accept it */
            effect_active = (tip == GPIO_PIN_RESET); /* L=on, H=bypass */
            update_signal_path();
            led_update_needed = 1;
        }
        if (ring != prev_latch_ring) {
            prev_latch_ring = ring;
            led_update_needed = 1;
        }
    }
}

/* The blink count equals the bias ratio (1:1=1, 2:1=2, 3:1=3, 4:1=4) */
static uint8_t get_bias_blink_count(GPIO_PinState pos1, GPIO_PinState pos3)
{
    if (dip_sw2) {
        /* Extended: up=4:1, center=3:1, down=2:1 */
        if (pos1 == GPIO_PIN_RESET && pos3 == GPIO_PIN_SET) return 4;
        if (pos1 == GPIO_PIN_SET && pos3 == GPIO_PIN_RESET) return 2;
        return 3;
    } else {
        /* Standard: up=3:1, center=2:1, down=1:1 */
        if (pos1 == GPIO_PIN_RESET && pos3 == GPIO_PIN_SET) return 3;
        if (pos1 == GPIO_PIN_SET && pos3 == GPIO_PIN_RESET) return 1;
        return 2;
    }
}

/* Response blink counts Steep=1 / Medium=2 / Gradual=3 */
static uint8_t get_response_blink_count(GPIO_PinState pos1, GPIO_PinState pos3)
{
    if (pos1 == GPIO_PIN_RESET && pos3 == GPIO_PIN_SET) return 3; /* up: Gradual */
    if (pos1 == GPIO_PIN_SET && pos3 == GPIO_PIN_RESET) return 1; /* down: Steep */
    return 2;                                                     /* Medium */
}

/* Input filter blink counts Single=1 / Hum=2 / Wah=3 */
static uint8_t get_filter_blink_count(GPIO_PinState pos1, GPIO_PinState pos3)
{
    if (pos1 == GPIO_PIN_RESET && pos3 == GPIO_PIN_SET) return 3; /* up: Wah      */
    if (pos1 == GPIO_PIN_SET && pos3 == GPIO_PIN_RESET) return 1; /* down: Single */
    return 2;                                                     /* Hum */
}

static void ind_seq_start(ind_seq_t *seq, uint8_t blinks)
{
    seq->blink_remain = blinks;
    seq->state        = IND_SEQ_SOLID_1S;
    seq->timer_ms     = IND_SOLID_MS;
    led_override      = seq->color;
    led_update_needed = 1;
}

/* The four indication sequences are mutually exclusive: a newly started one cancels the running one */
static void ind_seq_cancel_others(const ind_seq_t *keep)
{
    ind_seq_t *all[] = { &bias_seq, &resp_seq, &filter_seq, &learn_seq };
    for (unsigned i = 0; i < sizeof(all) / sizeof(all[0]); i++) {
        if (all[i] == keep) continue;
        all[i]->state    = IND_SEQ_IDLE;
        all[i]->timer_ms = 0;
    }
}

/* Advance one sequence by one SysTick. active: this sequence holds LED priority */
static void ind_seq_tick(ind_seq_t *seq, bool active)
{
    if (seq->timer_ms == 0) return;
    if (--seq->timer_ms != 0) return;

    switch (seq->state) {
        case IND_SEQ_SOLID_1S:
            seq->state    = IND_SEQ_BLINK_OFF;
            seq->timer_ms = IND_BLINK_OFF_MS;
            if (active) { led_override = LED_OVERRIDE_OFF; led_update_needed = 1; }
            break;
        case IND_SEQ_BLINK_OFF:
            seq->state    = IND_SEQ_BLINK_ON;
            seq->timer_ms = IND_BLINK_ON_MS;
            if (active) { led_override = seq->color; led_update_needed = 1; }
            break;
        case IND_SEQ_BLINK_ON:
            seq->blink_remain--;
            if (seq->blink_remain > 0) {
                seq->state    = IND_SEQ_BLINK_OFF;
                seq->timer_ms = IND_BLINK_OFF_MS;
                if (active) { led_override = LED_OVERRIDE_OFF; led_update_needed = 1; }
            } else {
                seq->state    = IND_SEQ_FINAL_OFF;
                seq->timer_ms = IND_FINAL_OFF_MS;
                if (active) { led_override = LED_OVERRIDE_OFF; led_update_needed = 1; }
            }
            break;
        case IND_SEQ_FINAL_OFF:
            seq->state = IND_SEQ_IDLE;
            if (active) { led_override = LED_OVERRIDE_NONE; led_update_needed = 1; }
            break;
        default:
            break;
    }
}

static void poll_bias_switch(void)
{
    GPIO_PinState pos1 = HAL_GPIO_ReadPin(GPIOB, GPIO_PIN_2);
    GPIO_PinState pos3 = HAL_GPIO_ReadPin(GPIOB, GPIO_PIN_3);
    if (pos1 != prev_bias_pos1 || pos3 != prev_bias_pos3) {
        prev_bias_pos1 = pos1;
        prev_bias_pos3 = pos3;
        bias_override = BIAS_OVR_NONE;   /* moving the toggle clears the MIDI override */
        update_bias_output();
        ind_seq_cancel_others(&bias_seq);
        ind_seq_start(&bias_seq, get_bias_blink_count(pos1, pos3));
    }
}

/* Response toggle (PB0/PB1) */
static void poll_response_switch(void)
{
    GPIO_PinState pos1 = HAL_GPIO_ReadPin(GPIOB, GPIO_PIN_0);
    GPIO_PinState pos3 = HAL_GPIO_ReadPin(GPIOB, GPIO_PIN_1);
    if (pos1 != prev_resp_pos1 || pos3 != prev_resp_pos3) {
        prev_resp_pos1 = pos1;
        prev_resp_pos3 = pos3;
        response_override = RESP_OVR_NONE;   /* moving the toggle clears the MIDI override */
        update_response_output();
        ind_seq_cancel_others(&resp_seq);
        ind_seq_start(&resp_seq, get_response_blink_count(pos1, pos3));
    }
}

static void poll_filter_switch(void)
{
    GPIO_PinState pos1 = HAL_GPIO_ReadPin(GPIOB, GPIO_PIN_10);
    GPIO_PinState pos3 = HAL_GPIO_ReadPin(GPIOB, GPIO_PIN_11);
    if (pos1 != prev_filt_pos1 || pos3 != prev_filt_pos3) {
        prev_filt_pos1 = pos1;
        prev_filt_pos3 = pos3;
        filter_override = FILT_OVR_NONE;   /* moving the toggle clears the MIDI override */
        update_filter_output();
        ind_seq_cancel_others(&filter_seq);
        ind_seq_start(&filter_seq, get_filter_blink_count(pos1, pos3));
    }
}

/* PB5 selects the J104 role through U107:
     H (latch mode): U109 closes and connects the Tip pull-up (+5V -> R127 3k3 -> U109 -> R144 470),
                     U110 opens, D110 lights.
     L (MIDI mode) : U109 opens, U110 closes and connects the Ring current source (+5V -> R131 -> U110
                     -> R132 -> Ring), D110 goes dark.
   PB5 no longer gates the MIDI-OUT driver (U108 is gone), so the firmware itself keeps USART1 TX
   silent in latch mode. */
static void update_mode_pb5(void)
{
    HAL_GPIO_WritePin(GPIOB, GPIO_PIN_5,
        dip_sw3 ? GPIO_PIN_RESET : GPIO_PIN_SET);
}

/* ---- Save/load the learned value to/from the EEPROM (M24C64) ---- */
/* Returns true if the write succeeded */
static bool eeprom_save_learn(void)
{
    uint8_t buf[4];
    buf[0] = LEARN_MAGIC;
    buf[1] = learn_ch;
    buf[2] = learn_cc;
    buf[3] = (uint8_t)(LEARN_MAGIC ^ learn_ch ^ learn_cc); /* checksum */
    if (HAL_I2C_Mem_Write(&hi2c2, EEPROM_I2C_ADDR, EEPROM_MEM_ADDR,
            I2C_MEMADD_SIZE_16BIT, buf, 4, 100) == HAL_OK) {
        HAL_Delay(5); /* M24C64 write cycle (5ms max) */
        return true;
    }
    return false;
}

static void eeprom_load_learn(void)
{
    uint8_t buf[4];
    if (HAL_I2C_Mem_Read(&hi2c2, EEPROM_I2C_ADDR, EEPROM_MEM_ADDR,
            I2C_MEMADD_SIZE_16BIT, buf, 4, 100) == HAL_OK) {
        if (buf[0] == LEARN_MAGIC && buf[1] < 16u && buf[2] < 128u &&
            buf[3] == (uint8_t)(LEARN_MAGIC ^ buf[1] ^ buf[2])) {
            learn_ch    = buf[1];
            learn_cc    = buf[2];
            learn_valid = true;
        }
    }
}

/* Post a CC event to the queue. Push only from the USART1 ISR or inside an __disable_irq()
   section (single producer). Only poll_midi advances the tail. New events are dropped when full. */
static void midi_evt_push(uint8_t ch, uint8_t cc, uint8_t val)
{
    uint8_t next = (uint8_t)((midi_evt_head + 1u) & (MIDI_EVT_SIZE - 1u));
    if (next == midi_evt_tail) { midi_evt_drop++; return; }   /* full: drop it (counted in midi_evt_drop) */
    midi_evt_buf[midi_evt_head].ch  = ch;
    midi_evt_buf[midi_evt_head].cc  = cc;
    midi_evt_buf[midi_evt_head].val = val;
    midi_evt_head = next;
    /* Record the high-water mark (depth just after the push; only the consumer moves tail) */
    uint8_t depth = (uint8_t)((next - midi_evt_tail) & (MIDI_EVT_SIZE - 1u));
    if (depth > midi_evt_qmax) midi_evt_qmax = depth;
}

/* Called from the ISR (or from MRECV injection): learn this CC, or post it as an event */
static void midi_handle_cc(uint8_t ch, uint8_t cc, uint8_t val)
{
    if (learn_armed) {
        /* Learn: store this message CH/CC and request an EEPROM write (poll_midi indicates it)*/
        learn_ch           = ch;
        learn_cc           = cc;
        learn_valid        = true;
        learn_armed        = false;
        learn_save_request = true;
    } else {
        midi_evt_push(ch, cc, val);
    }
}

/* CC83 Input: 0=revert / 1-31 Single / 32-63 Hum / 64-95 Wah / 96-127 All-OFF
   value 0 clears the override and returns to the physical toggle position.
   On revert, read the toggle and indicate with that position blink count (same UX as poll_filter_switch).

   Skip if equivalent: do nothing when the requested state equals the current one.
   "Current state" is the override variable itself (NONE = follow the toggle / POS1..POS4).
   With an idempotent assignment on the MIDI controller (SW1=value0, SW2=value1, ...), tapping the
   same footswitch repeatedly would restart the indication sequence and make the LED flicker.
   Note that with override=NONE, selecting over MIDI the position the toggle is already in leaves the
   output unchanged but changes the state (NONE -> set), so we do indicate: it stops following the toggle. */
static void apply_midi_input(uint8_t val)
{
    if (val == 0) {
        if (filter_override == FILT_OVR_NONE) return;  /* already following the toggle */
        filter_override = FILT_OVR_NONE;
        update_filter_output();
        ind_seq_cancel_others(&filter_seq);
        ind_seq_start(&filter_seq,
            get_filter_blink_count(HAL_GPIO_ReadPin(GPIOB, GPIO_PIN_10),
                                   HAL_GPIO_ReadPin(GPIOB, GPIO_PIN_11)));
        return;
    }
    filt_ovr_t o;
    uint8_t blinks;
    switch (val >> 5) {  /* 1-31 -> 0 / 32-63 -> 1 / 64-95 -> 2 / 96-127 -> 3 */
        case 0:  o = FILT_OVR_SINGLE; blinks = 1; break;
        case 1:  o = FILT_OVR_HUM;    blinks = 2; break;
        case 2:  o = FILT_OVR_WAH;    blinks = 3; break;
        default: o = FILT_OVR_ALLOFF; blinks = 4; break;
    }
    if (filter_override == o) return;   /* equivalent request -> no indication */
    filter_override = o;
    update_filter_output();
    ind_seq_cancel_others(&filter_seq);
    ind_seq_start(&filter_seq, blinks);
}

/* CC84 Response: 0=revert / 1-31 Steep / 32-63 Medium / 64-95 Gradual / 96-127 N/A (ignored)
   A request equivalent to the current override is ignored (see the notes on apply_midi_input) */
static void apply_midi_response(uint8_t val)
{
    if (val == 0) {
        if (response_override == RESP_OVR_NONE) return;  /* already following the toggle */
        response_override = RESP_OVR_NONE;
        update_response_output();
        ind_seq_cancel_others(&resp_seq);
        ind_seq_start(&resp_seq,
            get_response_blink_count(HAL_GPIO_ReadPin(GPIOB, GPIO_PIN_0),
                                     HAL_GPIO_ReadPin(GPIOB, GPIO_PIN_1)));
        return;
    }
    resp_ovr_t o;
    uint8_t blinks;
    switch (val >> 5) {
        case 0:  o = RESP_OVR_STEEP;   blinks = 1; break;
        case 1:  o = RESP_OVR_MEDIUM;  blinks = 2; break;
        case 2:  o = RESP_OVR_GRADUAL; blinks = 3; break;
        default: return;  /* 96-127 is N/A: leave unchanged */
    }
    if (response_override == o) return;   /* equivalent request -> no indication */
    response_override = o;
    update_response_output();
    ind_seq_cancel_others(&resp_seq);
    ind_seq_start(&resp_seq, blinks);
}

/* CC85 Bias: 0=revert / 1-31 Center / 32-63 Offset / 64-95 Skew / 96-127 X-Skew (PA10 PA11 High)
   A request equivalent to the current override is ignored (see the notes on apply_midi_input) */
static void apply_midi_bias(uint8_t val)
{
    if (val == 0) {
        if (bias_override == BIAS_OVR_NONE) return;  /* already following the toggle */
        bias_override = BIAS_OVR_NONE;
        update_bias_output();
        ind_seq_cancel_others(&bias_seq);
        ind_seq_start(&bias_seq,
            get_bias_blink_count(HAL_GPIO_ReadPin(GPIOB, GPIO_PIN_2),
                                 HAL_GPIO_ReadPin(GPIOB, GPIO_PIN_3)));
        return;
    }
    bias_ovr_t o;
    uint8_t blinks;
    switch (val >> 5) {
        case 0:  o = BIAS_OVR_CENTER; blinks = 1; break;
        case 1:  o = BIAS_OVR_OFFSET; blinks = 2; break;
        case 2:  o = BIAS_OVR_SKEW;   blinks = 3; break;
        default: o = BIAS_OVR_XSKEW;  blinks = 4; break;
    }
    if (bias_override == o) return;   /* equivalent request -> no indication */
    bias_override = o;
    update_bias_output();
    ind_seq_cancel_others(&bias_seq);
    ind_seq_start(&bias_seq, blinks);
}

/* Interpret and apply one received CC (called from poll_midi).
   MIDI-IN has its own jack and is always live, so MIDI control is accepted whatever
   the DIP switches say (latch or MIDI mode). In latch mode both the physical footswitch (latch
   input) and MIDI drive effect_active; last writer wins.
   - Effect on/off trigger: DIP-SW4 OFF = CH12 CC81 / ON = the learned CH+CC. value >= 64 turns it on
   - Toggle CCs 83/84/85: the "active channel" follows the same rule as on/off
     (DIP-SW4 OFF = fixed CH12 / ON = the learned CH). value 0 = revert, 1-127 split into four bands.
   A message matching the on/off trigger is handled as on/off and never tested as a toggle CC (on/off wins a CC number clash). */
static void midi_process_event(uint8_t ch, uint8_t cc, uint8_t val)
{
    midi_cc_rx++;   /* Total CCs that reached processing (reported by MSTAT) */

    /* --- effect on/off --- */
    bool onoff_match;
    if (dip_sw4) onoff_match = (learn_valid && ch == learn_ch && cc == learn_cc);
    else         onoff_match = (ch == TRIG_CH_FIXED && cc == TRIG_CC_FIXED);
    if (onoff_match) {
        bool new_val = (val >= 64u);
        if (effect_active != new_val) {
            effect_active = new_val;
            update_signal_path();
            led_update_needed = 1;
        }
        return;
    }

    /* --- toggle setting change (CC 83/84/85) --- */
    if (dip_sw4 && !learn_valid) return;  /* ignore until a channel has been learned */
    uint8_t active_ch = dip_sw4 ? learn_ch : TRIG_CH_FIXED;
    if (ch != active_ch) return;

    /* value 0 = revert to the physical toggle / 1-127 split into four bands (decided in each apply function). */
    switch (cc) {
        case TOGGLE_CC_INPUT:    apply_midi_input(val);    break;
        case TOGGLE_CC_RESPONSE: apply_midi_response(val); break;
        case TOGGLE_CC_BIAS:     apply_midi_bias(val);     break;
        default: break;
    }
}

/* Called from the main loop: service the EEPROM write request and drain the received-CC queue.
   MIDI control always applies, whatever the DIP switches say (MIDI-IN is always live on its own jack).
   Thru and Active Sensing stay MIDI-mode only: MIDI-OUT drives the same J104 Tip that the latch input
   reads, and nothing in hardware disables the driver in latch mode. */
static void poll_midi(void)
{
    if (learn_save_request) {
        learn_save_request = false;
        if (eeprom_save_learn()) {
            /* Saved: indicate the same way a toggle switch does (white, 3 blinks) */
            ind_seq_cancel_others(&learn_seq);
            ind_seq_start(&learn_seq, 3);
        } else {
            led_update_needed = 1; /* on failure, fall back to the normal display */
        }
    }

    while (midi_evt_tail != midi_evt_head) {   /* SPSC: this is the only place tail advances */
        uint8_t ch  = midi_evt_buf[midi_evt_tail].ch;
        uint8_t cc  = midi_evt_buf[midi_evt_tail].cc;
        uint8_t val = midi_evt_buf[midi_evt_tail].val;
        midi_evt_tail = (uint8_t)((midi_evt_tail + 1u) & (MIDI_EVT_SIZE - 1u));
        midi_process_event(ch, cc, val);   /* always applied, whatever the DIP switches say */
    }
}

/* Send Active Sensing (0xFE) to MIDI-OUT every 250ms (MIDI mode only).
   thru_send_byte() in the ISR also writes USART1->TDR, so the access is made atomic with __disable_irq().
   Testing and clearing the pending flag belongs in the same critical section - splitting them would
   lose a request raised by SysTick in the gap, stretching the interval to 500ms, past the 300ms spec.
   If TXE is not free, leave it pending and retry next loop rather than stalling interrupts.
   PB9 (the MIDI-OUT activity LED) is deliberately not lit: constant blinking would hide real traffic.

   Do not send within THRU_IDLE_GUARD_MS of a Thru byte, so 0xFE never lands in
   the middle of a Thru message (see the notes where THRU_IDLE_GUARD_MS is defined).
   midi_as_pending stays set while held back, so the byte goes out as soon as Thru falls idle.
   The thru_idle_ms test belongs in the same critical section as the TXE test and the TDR write -
   otherwise the ISR could send a Thru byte in the gap and we would interrupt a message after all. */
static void poll_midi_out_sensing(void)
{
    if (!dip_sw3) {           /* latch mode: Tip is the latch input, keep USART1 TX silent */
        midi_as_pending = false;
        return;
    }
    __disable_irq();
    if (midi_as_pending) {
        if (thru_idle_ms != 0) {
            /* Thru is active - hold back, keeping pending set. ASHOLD counts delayed 0xFE
               bytes, not polls, so count this pending only if it has not been counted yet. */
            if (!midi_as_held) { midi_as_held = true; midi_as_hold++; }
        } else if (USART1->ISR & USART_ISR_TXE) {
            USART1->TDR     = 0xFEu;   /* Active Sensing */
            midi_as_pending = false;
            midi_as_held    = false;
            midi_as_tx++;
            midi_mon_push(MIDI_MON_DIR_OUT, 0xFEu);  /* VCP debug: MIDI-OUT monitor */
        }
    }
    __enable_irq();
}

/* MIDI-Learn button (PC15). A press arms learning; pressing again while armed cancels it */
static void poll_midi_learn(void)
{
    if (pc15_debounce_ms > 0) return;
    GPIO_PinState cur = HAL_GPIO_ReadPin(GPIOC, GPIO_PIN_15);
    if (cur != prev_pc15) {
        prev_pc15 = cur;
        if (cur == GPIO_PIN_RESET) { /* H->L: pressed */
            if (learn_armed) {
                learn_armed      = false; /* cancel */
                learn_timeout_ms = 0;
            } else {
                learn_armed       = true; /* arm learning */
                learn_timeout_ms  = LEARN_TIMEOUT_MS;
                learn_blink_phase = 1;
                learn_blink_ms    = 0;
            }
            led_update_needed = 1;
        }
        pc15_debounce_ms = PC15_DEBOUNCE_MS;
    }
}

/* Send one byte to MIDI-OUT (PB6/USART1_TX) and light PB9.
   Sends nothing in latch mode (DIP-SW3 OFF), whatever the caller checked: MIDI-OUT shares the
   J104 Tip with the latch input on v1.1. */
static void thru_send_byte(uint8_t b)
{
    if (!dip_sw3) return;
    while (!(USART1->ISR & USART_ISR_TXE)) { }
    USART1->TDR = b;
    thru_idle_ms = THRU_IDLE_GUARD_MS;   /* keep our Active Sensing out of this message */
    midi_mon_push(MIDI_MON_DIR_OUT, b);  /* VCP debug: MIDI-OUT monitor (called in ISR context) */
    /* While VCP debug is active, freeze only the indicator; Thru itself keeps running */
    if (!dbg_active) {
        midi_out_indicator_ms = MIDI_INDICATOR_MS;
        HAL_GPIO_WritePin(GPIOB, GPIO_PIN_9, GPIO_PIN_SET);
    }
}

/* MIDI Thru proper - pass every received byte straight to MIDI-OUT, byte by byte.
   It holds no state at all, so interleaved messages, running status and System Real-Time bytes
   injected mid-message cannot cause a dropped byte or a misparse.
   Everything is forwarded verbatim, including our own toggle CCs and incoming Active Sensing (0xFE).
   (The old store-and-forward version buffered three bytes per CC and broke on interleaved input, so it was removed.)
   Our own 0xFE and the forwarded one both go out, but 0xFE is idempotent - it only resets a watchdog timer - so this is harmless. */
static void midi_thru_filter(uint8_t b)
{
    thru_send_byte(b);
}

/* MIDI byte parser proper - decodes Control Change (handles Running Status and Realtime).
   Shared by the USART1 ISR and MRECV injection (inside an __disable_irq() section). The parser
   state (midi_status/midi_state/midi_cc_num) is shared, so callers must be serialized. */
static void midi_parse_byte(uint8_t b)
{
    if (b >= 0xF8u) {
        /* System Real-Time (0xF8-0xFF): must not disturb the parser state */
    } else if (b & 0x80u) {
        /* Status byte: track Control Change (0xBn) only; anything else aborts the parse */
        if ((b & 0xF0u) == 0xB0u) {
            midi_status = b;
            midi_state  = MIDI_DATA1;
        } else {
            midi_state = MIDI_IDLE;
        }
    } else {
        /* Data byte */
        switch (midi_state) {
            case MIDI_DATA1:
                midi_cc_num = b;
                midi_state  = MIDI_DATA2;
                break;
            case MIDI_DATA2:
                midi_handle_cc(midi_status & 0x0Fu, midi_cc_num, b);
                midi_state = MIDI_DATA1; /* running status */
                break;
            default:
                break;
        }
    }
}

/* USART1 RX complete: log to the monitor, pulse the indicator and do Thru, then hand it to the parser */
void HAL_UART_RxCpltCallback(UART_HandleTypeDef *huart)
{
    if (huart->Instance != USART1) return;
    uint8_t b = midi_rx_buf;

    midi_mon_push(0, b);  /* VCP debug: MIDI-IN monitor */

    /* Light the MIDI-IN indicator PB8 whatever the DIP switches say (suppressed during VCP debug, where GPIO is frozen) */
    if (!dbg_active) {
        midi_indicator_ms = MIDI_INDICATOR_MS;
        HAL_GPIO_WritePin(GPIOB, GPIO_PIN_8, GPIO_PIN_SET);
    }

    /* MIDI Thru (every byte passed straight through) only in MIDI mode (DIP-SW3 ON). */
    if (dip_sw3) {
        midi_thru_filter(b);
    }

    midi_parse_byte(b);
    HAL_UART_Receive_IT(&huart1, (uint8_t *)&midi_rx_buf, 1);
}

/* MRECV: simulate MIDI-IN reception by feeding one byte to the parser (debug only).
   Wrapped in __disable_irq() so it cannot race the USART1 ISR (protects the parser state and the queue).
   Unlike a real byte it does not trigger Thru or light PB8, so only the CC control logic is exercised.
   The bytes are recorded in the monitor as 'I' and can be read back with the M command. */
static void midi_inject_rx_byte(uint8_t b)
{
    __disable_irq();
    midi_mon_push(0, b);
    midi_parse_byte(b);
    __enable_irq();
}

/* ---- PowerGood ADC (PA0=ADC_IN0) ----
   Read one conversion at a time with a single channel in CHSELR; this sidesteps the EOC/EOS ambiguity.
   The sampling time (239.5 cycles) is already in SMPR from MX_ADC_Init and applies to every channel.
   VREFEN was set in CCR when VREFINT was configured and stays set. */
static uint16_t adc_read_ch(uint32_t chselr_bit)
{
    uint16_t v = 0;
    hadc.Instance->CHSELR = chselr_bit;
    if (HAL_ADC_Start(&hadc) == HAL_OK) {
        if (HAL_ADC_PollForConversion(&hadc, 10) == HAL_OK) {
            v = (uint16_t)HAL_ADC_GetValue(&hadc);
        }
        HAL_ADC_Stop(&hadc);
    }
    return v;
}

/* Every PGOOD_POLL_MS, measure PA0 and VREFINT, estimate V_DDA from the VREFINT calibration value,
   compute the divider voltage [mV], and set power_good from the window (1.985~2.977V = 8.0~12.0V).
   PC13 itself is driven from SysTick based on power_good. */
static void measure_power_good(void)
{
    uint16_t pa0_raw  = adc_read_ch(ADC_CHSELR_CHSEL0);
    uint16_t vref_raw = adc_read_ch(ADC_CHSELR_CHSEL17);
    if (vref_raw == 0) {              /* measurement failed; avoid dividing by zero. Only a sim override applies */
        if (pg_sim) {
            bool pg = (pg_sim == 1);
            if (pg != power_good) { power_good = pg; led_update_needed = 1; }
        }
        return;
    }

    /* V_DDA[mV] = 3300 * VREFINT_CAL / VREFINT_measured */
    uint32_t vdda_mv = (VREFINT_CAL_VREF * (uint32_t)(*VREFINT_CAL_ADDR)) / vref_raw;
    /* divider voltage [mV] = V_DDA * ADC(PA0) / 4095 */
    uint32_t vpa0_mv = (vdda_mv * pa0_raw) / ADC_FULL_SCALE;

    bool pg;
    if (pg_sim == 1)      pg = true;   /* debug: force good */
    else if (pg_sim == 2) pg = false;  /* debug: force bad */
    else                  pg = (vpa0_mv >= PGOOD_DIV_LO_MV && vpa0_mv <= PGOOD_DIV_HI_MV);

    /* Refresh the main LED (PA7) on a good<->bad transition; PC13 is driven every tick by SysTick. */
    if (pg != power_good) { power_good = pg; led_update_needed = 1; }

    /* Keep the measurements for the S and ADC debug replies (always the real readings, even while simulating) */
    pgood_pa0_raw  = pa0_raw;
    pgood_vref_raw = vref_raw;
    pgood_vdda_mv  = vdda_mv;
    pgood_vpa0_mv  = vpa0_mv;
}

static void poll_power_good(void)
{
    if (pgood_poll_ms != 0) return;   /* wait while SysTick counts down */
    pgood_poll_ms = PGOOD_POLL_MS;    /* reload for the next one */
    measure_power_good();             /* split out so VCP debug can call the measurement directly */
}

/* ---- VCP debug console (USART2 PA2/PA3, STLINK-V3 VCP) ----
   ASCII line commands to drive GPIO outputs directly, monitor every pin and set the PL9823 color.
   While DBG is ON, normal main-loop control and the 1ms SysTick application work are stopped
   so that writes from outside are not overwritten.
   Commands: PING / DBG ON|OFF / W <pin> <0|1> / S / RGB <r> <g> <b> / ADC */

/* USART2 ISR body (called from USART2_IRQHandler in stm32f0xx_it.c).
   Reads RDR directly rather than going through HAL, accumulating into the line buffer */
void dbg_uart2_irqhandler(void)
{
    uint32_t isr = USART2->ISR;
    if (isr & (USART_ISR_ORE | USART_ISR_FE | USART_ISR_NE)) {
        USART2->ICR = USART_ICR_ORECF | USART_ICR_FECF | USART_ICR_NCF;
    }
    if (isr & USART_ISR_RXNE) {
        uint8_t b = (uint8_t)USART2->RDR;          /* the read clears RXNE */
        if (dbg_line_ready) return;                /* keep the line the main loop is using; drop new input */
        if (b == '\r' || b == '\n') {
            if (dbg_line_len > 0) {
                dbg_line[dbg_line_len] = '\0';
                dbg_line_ready = true;
            }
        } else if (dbg_line_len < DBG_LINE_MAX - 1u) {
            dbg_line[dbg_line_len++] = (char)b;
        } else {
            dbg_line_len = 0;                      /* discard the whole overflowing line and report it */
            dbg_line_overflow = true;
        }
    }
}

/* Blocking send on USART2 (same TXE busy-wait style as thru_send_byte) */
static void dbg_send_str(const char *s)
{
    while (*s) {
        while (!(USART2->ISR & USART_ISR_TXE)) { }
        USART2->TDR = (uint8_t)*s++;
    }
}

static const dbg_pin_t *dbg_find_pin(const char *name)
{
    for (unsigned i = 0; i < DBG_NUM_PINS; i++) {
        if (strcmp(dbg_pins[i].name, name) == 0) return &dbg_pins[i];
    }
    return NULL;
}

/* Record one byte in the MIDI monitor. Call only from the USART1 ISR or inside an __disable_irq() section */
static void midi_mon_push(uint16_t dir_flag, uint8_t b)
{
    uint8_t next = (uint8_t)((midi_mon_head + 1u) & (MIDI_MON_SIZE - 1u));
    if (next == midi_mon_tail) {
        midi_mon_drops++;   /* full: drop it and just count it */
        return;
    }
    midi_mon_buf[midi_mon_head] = (uint16_t)(dir_flag | b);
    midi_mon_head = next;
}

/* MSEND: send an arbitrary byte to MIDI-OUT (USART1) and record it in the monitor.
   Interrupts are disabled from the TXE wait through the TDR write, so this cannot race the TDR
   write in Thru (ISR). That lasts 320us at most, and the host is waiting for the VCP reply and
   sends nothing, so USART2 loses nothing.
   Latch mode (DIP-SW3 OFF) sends nothing: the byte would appear on the J104 Tip and PF0 would take it
   for a footswitch press. The MSEND handler rejects the command first; this check is the backstop. */
static void midi_inject_byte(uint8_t b)
{
    if (!dip_sw3) return;
    __disable_irq();
    while (!(USART1->ISR & USART_ISR_TXE)) { }
    USART1->TDR = b;
    midi_mon_push(MIDI_MON_DIR_OUT, b);
    __enable_irq();
}

/* M: drain the monitor buffer. Example reply: "OK M DROP=2 IFE OB0 O51 O7F" (I=in / O=out, plus two hex digits).
   Up to MIDI_MON_MAX_PER_RESP entries per call; the rest come back on the next M */
static void dbg_cmd_midi(void)
{
    __disable_irq();
    uint16_t drops = midi_mon_drops;
    midi_mon_drops = 0;
    __enable_irq();

    int n = snprintf(dbg_tx_buf, sizeof(dbg_tx_buf), "OK M");
    if (drops) {
        n += snprintf(dbg_tx_buf + n, sizeof(dbg_tx_buf) - (size_t)n, " DROP=%u", drops);
    }
    unsigned count = 0;
    while (midi_mon_tail != midi_mon_head && count < MIDI_MON_MAX_PER_RESP) {
        uint16_t e = midi_mon_buf[midi_mon_tail];
        midi_mon_tail = (uint8_t)((midi_mon_tail + 1u) & (MIDI_MON_SIZE - 1u));
        n += snprintf(dbg_tx_buf + n, sizeof(dbg_tx_buf) - (size_t)n, " %c%02X",
                      (e & MIDI_MON_DIR_OUT) ? 'O' : 'I', (unsigned)(e & 0xFFu));
        count++;
    }
    snprintf(dbg_tx_buf + n, sizeof(dbg_tx_buf) - (size_t)n, "\r\n");
    dbg_send_str(dbg_tx_buf);
}

/* LEARN: the stored MIDI-Learn value and the armed state. CH is reported 1-based, as MIDI convention has it */
static void dbg_cmd_learn(void)
{
    snprintf(dbg_tx_buf, sizeof(dbg_tx_buf),
             "OK LEARN VALID=%u CH=%u CC=%u ARMED=%u\r\n",
             learn_valid ? 1u : 0u, (unsigned)learn_ch + 1u, (unsigned)learn_cc,
             learn_armed ? 1u : 0u);
    dbg_send_str(dbg_tx_buf);
}

/* DBG OFF: return to normal control. Re-snapshot the inputs so that changes made during debug do
   not trigger anything, then restore the outputs to the state the firmware believes in */
static void dbg_exit(void)
{
    dbg_active = false;

    /* DBG may have written PB5 (W PB5 0 removes the Tip pull-up), so restore it and let Tip settle
       before the latch inputs are re-read */
    update_mode_pb5();
    HAL_Delay(LATCH_PULLUP_SETTLE_MS);

    /* Re-snapshot the inputs (same approach as on a dip_sw3 change) */
    latch_snapshot();       /* PF0/PF1 + Tip debounce state */
    prev_bias_pos1  = HAL_GPIO_ReadPin(GPIOB, GPIO_PIN_2);
    prev_bias_pos3  = HAL_GPIO_ReadPin(GPIOB, GPIO_PIN_3);
    prev_resp_pos1  = HAL_GPIO_ReadPin(GPIOB, GPIO_PIN_0);
    prev_resp_pos3  = HAL_GPIO_ReadPin(GPIOB, GPIO_PIN_1);
    prev_filt_pos1  = HAL_GPIO_ReadPin(GPIOB, GPIO_PIN_10);
    prev_filt_pos3  = HAL_GPIO_ReadPin(GPIOB, GPIO_PIN_11);
    prev_footsw     = HAL_GPIO_ReadPin(GPIOA, GPIO_PIN_12);
    prev_pc15       = HAL_GPIO_ReadPin(GPIOC, GPIO_PIN_15);

    /* Discard stale events and indications from the debug session (override state is real state, so keep it) */
    midi_evt_tail    = midi_evt_head;   /* empty the received-CC queue */
    ind_seq_cancel_others(NULL);
    led_override     = LED_OVERRIDE_NONE;
    learn_armed      = false;
    learn_timeout_ms = 0;
    /* The 1ms SysTick work is frozen during DBG, so thru_idle_ms never counts down.
       Clear it explicitly on exit, or Active Sensing would be held back for no reason */
    thru_idle_ms     = 0;

    /* Restore the outputs to the normal control state (update_signal_path also refreshes bias/response/filter).
       PB5 was restored above, before the re-snapshot */
    update_signal_path();
    led_update_needed = 1;  /* update_led() + ws_send() on the next loop */
}

/* Reply with a one-line snapshot of all 28 pins. Output pins are read from IDR (the actual pin level)
   too, so a mismatch between the driven and the real level - an external short, say - also shows up */
static void dbg_cmd_snapshot(void)
{
    measure_power_good();  /* return a fresh reading even while SysTick is frozen */
    int n = snprintf(dbg_tx_buf, sizeof(dbg_tx_buf), "OK S DBG=%u EFF=%u",
                     dbg_active ? 1u : 0u, effect_active ? 1u : 0u);
    for (unsigned i = 0; i < DBG_NUM_PINS; i++) {
        n += snprintf(dbg_tx_buf + n, sizeof(dbg_tx_buf) - (size_t)n, " %s=%u",
                      dbg_pins[i].name,
                      (HAL_GPIO_ReadPin(dbg_pins[i].port, dbg_pins[i].pin) == GPIO_PIN_SET) ? 1u : 0u);
    }
    snprintf(dbg_tx_buf + n, sizeof(dbg_tx_buf) - (size_t)n,
             " RGB=%u,%u,%u VPA0=%lu PG=%u FOVR=%u ROVR=%u BOVR=%u\r\n",
             led_data[0][0], led_data[0][1], led_data[0][2],
             (unsigned long)pgood_vpa0_mv, power_good ? 1u : 0u,
             (unsigned)filter_override, (unsigned)response_override,
             (unsigned)bias_override);
    dbg_send_str(dbg_tx_buf);
}

/* Report the MIDI receive health counters (MSTAT) or clear them (MSTAT CLR).
   Used in burst tests to show numerically that N messages sent means N processed and the queue never overflowed.
   QMAX is the high-water mark since the last clear, so CLR -> burst -> MSTAT gives the measured depth of that burst. */
static void dbg_cmd_mstat(bool clear)
{
    if (clear) {
        __disable_irq();
        midi_rx_err = 0; midi_evt_drop = 0; midi_evt_qmax = 0; midi_cc_rx = 0;
        midi_as_tx  = 0; midi_as_hold  = 0; midi_as_held = false;
        __enable_irq();
        dbg_send_str("OK MSTAT CLR\r\n");
        return;
    }
    __disable_irq();
    uint16_t err = midi_rx_err, drop = midi_evt_drop, cc = midi_cc_rx;
    uint16_t astx = midi_as_tx, ashold = midi_as_hold;
    uint8_t  qmax = midi_evt_qmax;
    uint8_t  qnow = (uint8_t)((midi_evt_head - midi_evt_tail) & (MIDI_EVT_SIZE - 1u));
    __enable_irq();
    snprintf(dbg_tx_buf, sizeof(dbg_tx_buf),
             "OK MSTAT RXERR=%u QDROP=%u QMAX=%u QNOW=%u QSIZE=%u CCRX=%u"
             " ASTX=%u ASHOLD=%u\r\n",
             err, drop, qmax, qnow, (unsigned)MIDI_EVT_SIZE, cc, astx, ashold);
    dbg_send_str(dbg_tx_buf);
}

static void dbg_cmd_adc(void)
{
    measure_power_good();
    snprintf(dbg_tx_buf, sizeof(dbg_tx_buf),
             "OK ADC PA0=%u VREF=%u VDDA=%lu VPA0=%lu PG=%u\r\n",
             pgood_pa0_raw, pgood_vref_raw,
             (unsigned long)pgood_vdda_mv, (unsigned long)pgood_vpa0_mv,
             power_good ? 1u : 0u);
    dbg_send_str(dbg_tx_buf);
}

/* Parse and execute a completed command line and reply with one line (called on every main-loop pass) */
static void poll_debug_uart(void)
{
    if (dbg_line_overflow) {
        dbg_line_overflow = false;
        dbg_send_str("ERR OVF\r\n");
    }
    if (!dbg_line_ready) return;

    /* The ISR leaves the buffer alone while ready==true, so copying then clearing needs no lock */
    char line[DBG_LINE_MAX];
    strcpy(line, (const char *)dbg_line);
    dbg_line_len   = 0;
    dbg_line_ready = false;

    for (char *c = line; *c; c++) {
        if (*c >= 'a' && *c <= 'z') *c -= 'a' - 'A';
    }

    char *tok[12] = { NULL };  /* MSEND plus up to 11 data bytes */
    int ntok = 0;
    for (char *c = strtok(line, " "); c && ntok < 12; c = strtok(NULL, " ")) {
        tok[ntok++] = c;
    }
    if (ntok == 0) return;

    if (strcmp(tok[0], "PING") == 0) {
        dbg_send_str("OK PONG v2\r\n");
    } else if (strcmp(tok[0], "DBG") == 0) {
        if (ntok == 2 && strcmp(tok[1], "ON") == 0) {
            dbg_active = true;
            dbg_send_str("OK DBG=1\r\n");
        } else if (ntok == 2 && strcmp(tok[1], "OFF") == 0) {
            dbg_exit();
            dbg_send_str("OK DBG=0\r\n");
        } else {
            dbg_send_str("ERR ARG\r\n");
        }
    } else if (strcmp(tok[0], "W") == 0) {
        if (!dbg_active) { dbg_send_str("ERR NOTDBG\r\n"); return; }
        if (ntok != 3 || (strcmp(tok[2], "0") != 0 && strcmp(tok[2], "1") != 0)) {
            dbg_send_str("ERR ARG\r\n");
            return;
        }
        const dbg_pin_t *p = dbg_find_pin(tok[1]);
        if (p == NULL || !p->writable) { dbg_send_str("ERR PIN\r\n"); return; }
        HAL_GPIO_WritePin(p->port, p->pin,
            (tok[2][0] == '1') ? GPIO_PIN_SET : GPIO_PIN_RESET);
        snprintf(dbg_tx_buf, sizeof(dbg_tx_buf), "OK %s=%c\r\n", p->name, tok[2][0]);
        dbg_send_str(dbg_tx_buf);
    } else if (strcmp(tok[0], "S") == 0) {
        dbg_cmd_snapshot();
    } else if (strcmp(tok[0], "RGB") == 0) {
        if (!dbg_active) { dbg_send_str("ERR NOTDBG\r\n"); return; }
        if (ntok != 4) { dbg_send_str("ERR ARG\r\n"); return; }
        long rv[3];
        for (int i = 0; i < 3; i++) {
            char *end = NULL;
            rv[i] = strtol(tok[i + 1], &end, 10);
            if (end == tok[i + 1] || *end != '\0' || rv[i] < 0 || rv[i] > 255) {
                dbg_send_str("ERR ARG\r\n");
                return;
            }
        }
        led_data[0][0] = (uint8_t)rv[0];
        led_data[0][1] = (uint8_t)rv[1];
        led_data[0][2] = (uint8_t)rv[2];
        ws_send();
        snprintf(dbg_tx_buf, sizeof(dbg_tx_buf), "OK RGB=%ld,%ld,%ld\r\n", rv[0], rv[1], rv[2]);
        dbg_send_str(dbg_tx_buf);
    } else if (strcmp(tok[0], "ADC") == 0) {
        dbg_cmd_adc();
    } else if (strcmp(tok[0], "M") == 0) {
        dbg_cmd_midi();
    } else if (strcmp(tok[0], "MSTAT") == 0) {
        /* MSTAT [CLR] - read or clear the MIDI receive health counters. Always available */
        if (ntok == 1)                              dbg_cmd_mstat(false);
        else if (ntok == 2 && strcmp(tok[1], "CLR") == 0) dbg_cmd_mstat(true);
        else                                        dbg_send_str("ERR ARG\r\n");
    } else if (strcmp(tok[0], "LEARN") == 0) {
        dbg_cmd_learn();
    } else if (strcmp(tok[0], "MSEND") == 0) {
        /* MSEND <hex> [hex...] - send an arbitrary byte sequence to MIDI-OUT (no DBG mode needed).
           All tokens are validated first, so a bad one never leaves a partial message on the wire.
           Latch mode (DIP-SW3 OFF) replies "ERR LATCH" and sends nothing (see midi_inject_byte).
           The arguments are checked before the mode, so a malformed command gets "ERR ARG" in
           either mode.
           Known limit in DBG mode: the main loop skips the DIP poll while DBG is ON, so dip_sw3
           keeps the value it had when DBG was entered. If DBG was entered in MIDI mode and SW3 is
           then turned OFF, this check and the one in midi_inject_byte still pass, and the bytes
           reach the J104 Tip. Thru (thru_send_byte) keeps running in DBG mode behind the same
           stale flag. The next DIP poll after DBG OFF picks up the new SW3 position. */
        if (ntok < 2) { dbg_send_str("ERR ARG\r\n"); return; }
        uint8_t bytes[11];
        for (int i = 1; i < ntok; i++) {
            char *end = NULL;
            long v = strtol(tok[i], &end, 16);
            if (end == tok[i] || *end != '\0' || v < 0 || v > 255) {
                dbg_send_str("ERR ARG\r\n");
                return;
            }
            bytes[i - 1] = (uint8_t)v;
        }
        if (!dip_sw3) { dbg_send_str("ERR LATCH\r\n"); return; }
        for (int i = 0; i < ntok - 1; i++) {
            midi_inject_byte(bytes[i]);
        }
        snprintf(dbg_tx_buf, sizeof(dbg_tx_buf), "OK MSEND %d\r\n", ntok - 1);
        dbg_send_str(dbg_tx_buf);
    } else if (strcmp(tok[0], "MRECV") == 0) {
        /* MRECV <hex> [hex...] - simulate MIDI-IN reception by injecting into the parser (no DBG mode needed).
           The effect is applied by the normal control loop (poll_midi), so use it with DBG OFF.
           Toggle and on/off control take effect in either DIP-SW3 position (MIDI-IN is always live). */
        if (ntok < 2) { dbg_send_str("ERR ARG\r\n"); return; }
        uint8_t bytes[11];
        for (int i = 1; i < ntok; i++) {
            char *end = NULL;
            long v = strtol(tok[i], &end, 16);
            if (end == tok[i] || *end != '\0' || v < 0 || v > 255) {
                dbg_send_str("ERR ARG\r\n");
                return;
            }
            bytes[i - 1] = (uint8_t)v;
        }
        for (int i = 0; i < ntok - 1; i++) {
            midi_inject_rx_byte(bytes[i]);
        }
        snprintf(dbg_tx_buf, sizeof(dbg_tx_buf), "OK MRECV %d\r\n", ntok - 1);
        dbg_send_str(dbg_tx_buf);
    } else if (strcmp(tok[0], "EDLY") == 0) {
        /* EDLY [us] - read or set the PA8 (Effect) falling-edge delay in us (no DBG mode needed).
           0 disables the delay (immediate OFF). Upper bound is EFFECT_OFF_DELAY_MAX.
           An experiment knob for sweeping the delay and comparing how the pop sounds; it reverts to the default on power-down. */
        if (ntok == 1) {
            snprintf(dbg_tx_buf, sizeof(dbg_tx_buf), "OK EDLY US=%u ARMED=%u N=%u\r\n",
                     (unsigned)effect_off_delay_us, effect_off_armed ? 1u : 0u,
                     (unsigned)effect_off_count);
            dbg_send_str(dbg_tx_buf);
        } else if (ntok == 2) {
            char *end = NULL;
            long v = strtol(tok[1], &end, 10);
            if (end == tok[1] || *end != '\0' || v < 0 || v > (long)EFFECT_OFF_DELAY_MAX) {
                dbg_send_str("ERR ARG\r\n");
                return;
            }
            /* If one is armed its expiry still uses the old value, so discard it. Cancelling alone
               would leave PA8 stuck High, so drive it Low here and settle the OFF */
            bool was_armed = effect_off_armed;
            effect_off_cancel();
            if (was_armed) HAL_GPIO_WritePin(GPIOA, GPIO_PIN_8, GPIO_PIN_RESET);
            effect_off_delay_us = (uint16_t)v;
            snprintf(dbg_tx_buf, sizeof(dbg_tx_buf), "OK EDLY US=%ld\r\n", v);
            dbg_send_str(dbg_tx_buf);
        } else {
            dbg_send_str("ERR ARG\r\n");
        }
    } else if (strcmp(tok[0], "PGSIM") == 0) {
        /* PGSIM 0|1|AUTO - force the PowerGood state (0=bad / 1=good) or return to AUTO (measured), for testing.
           Lets you check the main LED PG blink without varying the supply. Use with DBG OFF; it takes effect on the next (immediate) measurement. */
        if (ntok != 2) { dbg_send_str("ERR ARG\r\n"); return; }
        if (strcmp(tok[1], "AUTO") == 0)      pg_sim = 0;
        else if (strcmp(tok[1], "1") == 0)    pg_sim = 1;
        else if (strcmp(tok[1], "0") == 0)    pg_sim = 2;
        else { dbg_send_str("ERR ARG\r\n"); return; }
        pgood_poll_ms = 0;   /* measure and apply immediately on the next loop */
        snprintf(dbg_tx_buf, sizeof(dbg_tx_buf), "OK PGSIM %s\r\n", tok[1]);
        dbg_send_str(dbg_tx_buf);
    } else {
        dbg_send_str("ERR CMD\r\n");
    }
}

void HAL_SYSTICK_Callback(void)
{
    /* Freeze the 1ms application work while in VCP debug mode (uwTick/HAL_Delay keep running in SysTick_Handler).
       On exit, dbg_exit() explicitly resets the indication sequences and the rest */
    if (dbg_active) return;

    if (footsw_debounce_ms > 0) footsw_debounce_ms--;
    if (pc15_debounce_ms  > 0) pc15_debounce_ms--;
    if (pgood_poll_ms     > 0) pgood_poll_ms--;
    if (led_fade_ms       > 0) led_fade_ms--;   /* LED color fade step interval */
    if (thru_idle_ms      > 0) thru_idle_ms--;  /* AS guard after a Thru byte */

    /* Last-started sequence wins; only one runs at a time due to mutual cancel */
    ind_seq_tick(&bias_seq,   true);
    ind_seq_tick(&resp_seq,   true);
    ind_seq_tick(&filter_seq, true);
    ind_seq_tick(&learn_seq,  true); /* MIDI-Learn store-complete indication (white, 3 blinks)*/

    /* MIDI-OUT Active Sensing: raise a send request every 250ms (the main loop does the sending) */
    if (--midi_as_timer_ms == 0) {
        midi_as_timer_ms = MIDI_AS_INTERVAL_MS;
        midi_as_pending  = true;
    }

    /* MIDI-Learn: blink white while armed, auto-cancel on timeout */
    if (learn_armed) {
        if (++learn_blink_ms >= LEARN_BLINK_MS) {
            learn_blink_ms = 0;
            learn_blink_phase = !learn_blink_phase;
            led_update_needed = 1;
        }
        if (learn_timeout_ms > 0) {
            if (--learn_timeout_ms == 0) {
                learn_armed = false; /* timed out */
                led_update_needed = 1;
            }
        }
    }

    /* Heartbeat LED PC14 - blinks continuously with a 1s period.
       PC14 drives D114 only (v1.1 removed D115, the inverted twin that the 74HCT04 used to drive) */
    if (++startup_blink_ms >= STARTUP_BLINK_MS) {
        startup_blink_ms = 0;
        startup_blink_phase = !startup_blink_phase;
        HAL_GPIO_WritePin(GPIOC, GPIO_PIN_14,
            startup_blink_phase ? GPIO_PIN_SET : GPIO_PIN_RESET);
    }

    /* MIDI-IN activity indicator PB8 - turned off when the countdown expires */
    if (midi_indicator_ms > 0) {
        if (--midi_indicator_ms == 0) {
            HAL_GPIO_WritePin(GPIOB, GPIO_PIN_8, GPIO_PIN_RESET);
        }
    }

    /* MIDI-OUT (Thru) activity indicator PB9 - turned off when the countdown expires */
    if (midi_out_indicator_ms > 0) {
        if (--midi_out_indicator_ms == 0) {
            HAL_GPIO_WritePin(GPIOB, GPIO_PIN_9, GPIO_PIN_RESET);
        }
    }

    /* PowerGood status LED PC13 - solid inside the window / blinking at 0.4s (50% duty) outside it.
       Outside the window the main LED (PA7) blinks in the same phase, so raise led_update_needed
       on every phase flip to make the main loop redraw (update_led picks the color). */
    if (power_good) {
        HAL_GPIO_WritePin(GPIOC, GPIO_PIN_13, GPIO_PIN_SET);
        pgood_blink_ms = 0;
        pgood_blink_phase = 1;
    } else {
        if (++pgood_blink_ms >= PGOOD_BLINK_MS) {
            pgood_blink_ms = 0;
            pgood_blink_phase = !pgood_blink_phase;
            HAL_GPIO_WritePin(GPIOC, GPIO_PIN_13,
                pgood_blink_phase ? GPIO_PIN_SET : GPIO_PIN_RESET);
            led_update_needed = 1;   /* advance the main LED PG blink by one phase */
        }
    }
}

/* USER CODE END 0 */

int main(void)
{

  /* MCU Configuration--------------------------------------------------------*/

  /* Reset of all peripherals, Initializes the Flash interface and the Systick. */
  HAL_Init();

  /* Configure the system clock */
  SystemClock_Config();

  /* Initialize all configured peripherals */
  MX_GPIO_Init();
  MX_I2C2_Init();
  MX_TIM14_Init();
  MX_USART1_UART_Init();
  MX_USART2_UART_Init();
  MX_ADC_Init();
  /* USER CODE BEGIN 2 */
  /* Override PA7 AF (set by TIM14 MspPostInit) to GPIO push-pull for bit-banging */
  {
    GPIO_InitTypeDef gi = {0};
    gi.Pin   = GPIO_PIN_7;
    gi.Mode  = GPIO_MODE_OUTPUT_PP;
    gi.Pull  = GPIO_NOPULL;
    gi.Speed = GPIO_SPEED_FREQ_HIGH;
    HAL_GPIO_Init(GPIOA, &gi);
    HAL_GPIO_WritePin(GPIOA, GPIO_PIN_7, GPIO_PIN_RESET);
  }

  /* Wait for internal pull-ups to settle before reading DIP switches */
  HAL_Delay(10);

  /* Read DIP switches once at power-on (pull-up: ON=Low) */
  dip_sw1 = (HAL_GPIO_ReadPin(GPIOA, GPIO_PIN_4)  == GPIO_PIN_RESET);
  dip_sw2 = (HAL_GPIO_ReadPin(GPIOA, GPIO_PIN_5)  == GPIO_PIN_RESET);
  dip_sw3 = (HAL_GPIO_ReadPin(GPIOA, GPIO_PIN_6)  == GPIO_PIN_RESET);
  dip_sw4 = (HAL_GPIO_ReadPin(GPIOA, GPIO_PIN_15) == GPIO_PIN_RESET);

  /* PB5: connect the Tip pull-up (latch mode) before the snapshot below reads Tip, then let it settle.
     MX_GPIO_Init leaves PB5 Low, so reading first would sample a Tip with no pull-up. */
  update_mode_pb5();
  HAL_Delay(LATCH_PULLUP_SETTLE_MS);

  /* Initial input snapshot */
  latch_snapshot();       /* PF0/PF1 + Tip debounce state */
  prev_bias_pos1  = HAL_GPIO_ReadPin(GPIOB, GPIO_PIN_2);
  prev_bias_pos3  = HAL_GPIO_ReadPin(GPIOB, GPIO_PIN_3);
  prev_resp_pos1  = HAL_GPIO_ReadPin(GPIOB, GPIO_PIN_0);
  prev_resp_pos3  = HAL_GPIO_ReadPin(GPIOB, GPIO_PIN_1);
  prev_filt_pos1  = HAL_GPIO_ReadPin(GPIOB, GPIO_PIN_10);
  prev_filt_pos3  = HAL_GPIO_ReadPin(GPIOB, GPIO_PIN_11);
  prev_footsw     = HAL_GPIO_ReadPin(GPIOA, GPIO_PIN_12);
  prev_pc15       = HAL_GPIO_ReadPin(GPIOC, GPIO_PIN_15);

  /* MIDI-Learn: load the stored CH/CC from the EEPROM (M24C64) */
  eeprom_load_learn();

  /* Initial effect state: DIP-SW1, overridden by latch Tip if low.
   * The latch-level override applies ONLY in latch mode (SW4 OFF, non-MIDI).
   * In momentary mode (SW4 ON) PF0 is a pushbutton, not a latch level, so
   * its power-on level must not force the effect on - start follows DIP-SW1. */
  effect_active = dip_sw1;
  if (!dip_sw3 && !dip_sw4 && prev_latch_tip == GPIO_PIN_RESET) {
    effect_active = true;
  }

  /* PB5 was already set before the input snapshot */
  update_signal_path();
  update_led();
  ws_send();

  /* Start MIDI IN interrupt receive (USART1, 31250bps) */
  HAL_UART_Receive_IT(&huart1, (uint8_t *)&midi_rx_buf, 1);

  /* PowerGood ADC: calibrate (with ADEN=0), then take the first measurement to settle PC13 */
  HAL_ADCEx_Calibration_Start(&hadc);
  pgood_poll_ms = 0;      /* allow the first measurement */
  poll_power_good();
  HAL_GPIO_WritePin(GPIOC, GPIO_PIN_13,
      power_good ? GPIO_PIN_SET : GPIO_PIN_RESET);

  /* VCP debug console: boot banner, to confirm the board is alive after flashing */
  dbg_send_str("BOOT anthracite-" FW_VERSION " dbg v2 EDLY=5800us\r\n");
  /* USER CODE END 2 */

  /* Infinite loop */
  while (1)
  {

    /* USER CODE BEGIN 3 */
    /* VCP debug console: command handling. While DBG is ON, all normal control stops so the
       poll_* functions cannot overwrite GPIO/LED writes made from outside */
    poll_debug_uart();
    if (dbg_active) {
      continue;
    }

    /* Poll DIP-SW2/SW3/SW4 for runtime changes (always) */
    bool new_dip_sw2 = (HAL_GPIO_ReadPin(GPIOA, GPIO_PIN_5)  == GPIO_PIN_RESET);
    bool new_dip_sw3 = (HAL_GPIO_ReadPin(GPIOA, GPIO_PIN_6)  == GPIO_PIN_RESET);
    bool new_dip_sw4 = (HAL_GPIO_ReadPin(GPIOA, GPIO_PIN_15) == GPIO_PIN_RESET);
    if (new_dip_sw2 != dip_sw2) {
      dip_sw2 = new_dip_sw2;
      update_bias_output();
    }
    if (new_dip_sw3 != dip_sw3) {
      dip_sw3 = new_dip_sw3;
      update_mode_pb5(); /* PB5: Tip pull-up on in latch mode, off in MIDI mode */
      HAL_Delay(LATCH_PULLUP_SETTLE_MS); /* let Tip settle before reading it */
      /* Re-snapshot latch inputs to avoid a false trigger on mode re-entry */
      latch_snapshot();       /* PF0/PF1 + Tip debounce state */
    }
    if (new_dip_sw4 != dip_sw4) {
      dip_sw4 = new_dip_sw4; /* latch mode <-> momentary mode */
      /* Re-snapshot latch inputs to avoid a false trigger on the mode change */
      latch_snapshot();       /* PF0/PF1 + Tip debounce state */
    }

    poll_latch_input();
    poll_midi();
    poll_midi_out_sensing();
    poll_footswitch();
    poll_bias_switch();
    poll_response_switch();
    poll_filter_switch();
    poll_midi_learn();
    poll_power_good();

    if (led_update_needed) {
      led_update_needed = 0;
      update_led();      /* only updates the target color (led_target); poll_led_fade sends it */
    }
    poll_led_fade();     /* ease led_data toward led_target; ws_send only when it changed */
  }
  /* USER CODE END 3 */
}

void SystemClock_Config(void)
{
  RCC_OscInitTypeDef RCC_OscInitStruct = {0};
  RCC_ClkInitTypeDef RCC_ClkInitStruct = {0};
  RCC_PeriphCLKInitTypeDef PeriphClkInit = {0};

  /** Initializes the RCC Oscillators according to the specified parameters
  * in the RCC_OscInitTypeDef structure.
  */
  RCC_OscInitStruct.OscillatorType = RCC_OSCILLATORTYPE_HSI|RCC_OSCILLATORTYPE_HSI14;
  RCC_OscInitStruct.HSIState = RCC_HSI_ON;
  RCC_OscInitStruct.HSI14State = RCC_HSI14_ON;
  RCC_OscInitStruct.HSICalibrationValue = RCC_HSICALIBRATION_DEFAULT;
  RCC_OscInitStruct.HSI14CalibrationValue = 16;
  RCC_OscInitStruct.PLL.PLLState = RCC_PLL_ON;
  RCC_OscInitStruct.PLL.PLLSource = RCC_PLLSOURCE_HSI;
  RCC_OscInitStruct.PLL.PLLMUL = RCC_PLL_MUL12;
  RCC_OscInitStruct.PLL.PREDIV = RCC_PREDIV_DIV1;
  if (HAL_RCC_OscConfig(&RCC_OscInitStruct) != HAL_OK)
  {
    Error_Handler();
  }

  /** Initializes the CPU, AHB and APB buses clocks
  */
  RCC_ClkInitStruct.ClockType = RCC_CLOCKTYPE_HCLK|RCC_CLOCKTYPE_SYSCLK
                              |RCC_CLOCKTYPE_PCLK1;
  RCC_ClkInitStruct.SYSCLKSource = RCC_SYSCLKSOURCE_PLLCLK;
  RCC_ClkInitStruct.AHBCLKDivider = RCC_SYSCLK_DIV1;
  RCC_ClkInitStruct.APB1CLKDivider = RCC_HCLK_DIV1;

  if (HAL_RCC_ClockConfig(&RCC_ClkInitStruct, FLASH_LATENCY_1) != HAL_OK)
  {
    Error_Handler();
  }
  PeriphClkInit.PeriphClockSelection = RCC_PERIPHCLK_USART1;
  PeriphClkInit.Usart1ClockSelection = RCC_USART1CLKSOURCE_PCLK1;
  if (HAL_RCCEx_PeriphCLKConfig(&PeriphClkInit) != HAL_OK)
  {
    Error_Handler();
  }
}

static void MX_ADC_Init(void)
{

  ADC_ChannelConfTypeDef sConfig = {0};

  /** Configure the global features of the ADC (Clock, Resolution, Data Alignment and number of conversion)
  */
  hadc.Instance = ADC1;
  hadc.Init.ClockPrescaler = ADC_CLOCK_ASYNC_DIV1;
  hadc.Init.Resolution = ADC_RESOLUTION_12B;
  hadc.Init.DataAlign = ADC_DATAALIGN_RIGHT;
  hadc.Init.ScanConvMode = ADC_SCAN_DIRECTION_FORWARD;
  hadc.Init.EOCSelection = ADC_EOC_SINGLE_CONV;
  hadc.Init.LowPowerAutoWait = DISABLE;
  hadc.Init.LowPowerAutoPowerOff = DISABLE;
  hadc.Init.ContinuousConvMode = DISABLE;
  hadc.Init.DiscontinuousConvMode = DISABLE;
  hadc.Init.ExternalTrigConv = ADC_SOFTWARE_START;
  hadc.Init.ExternalTrigConvEdge = ADC_EXTERNALTRIGCONVEDGE_NONE;
  hadc.Init.DMAContinuousRequests = DISABLE;
  hadc.Init.Overrun = ADC_OVR_DATA_PRESERVED;
  if (HAL_ADC_Init(&hadc) != HAL_OK)
  {
    Error_Handler();
  }

  /** Configure for the selected ADC regular channel to be converted.
  */
  sConfig.Channel = ADC_CHANNEL_0;
  sConfig.Rank = ADC_RANK_CHANNEL_NUMBER;
  sConfig.SamplingTime = ADC_SAMPLETIME_239CYCLES_5;
  if (HAL_ADC_ConfigChannel(&hadc, &sConfig) != HAL_OK)
  {
    Error_Handler();
  }

  /** Configure for the selected ADC regular channel to be converted.
  */
  sConfig.Channel = ADC_CHANNEL_VREFINT;
  if (HAL_ADC_ConfigChannel(&hadc, &sConfig) != HAL_OK)
  {
    Error_Handler();
  }

}

static void MX_I2C2_Init(void)
{

  hi2c2.Instance = I2C2;
  hi2c2.Init.Timing = 0x10805D88;
  hi2c2.Init.OwnAddress1 = 0;
  hi2c2.Init.AddressingMode = I2C_ADDRESSINGMODE_7BIT;
  hi2c2.Init.DualAddressMode = I2C_DUALADDRESS_DISABLE;
  hi2c2.Init.OwnAddress2 = 0;
  hi2c2.Init.OwnAddress2Masks = I2C_OA2_NOMASK;
  hi2c2.Init.GeneralCallMode = I2C_GENERALCALL_DISABLE;
  hi2c2.Init.NoStretchMode = I2C_NOSTRETCH_DISABLE;
  if (HAL_I2C_Init(&hi2c2) != HAL_OK)
  {
    Error_Handler();
  }

  /** Configure Analogue filter
  */
  if (HAL_I2CEx_ConfigAnalogFilter(&hi2c2, I2C_ANALOGFILTER_ENABLE) != HAL_OK)
  {
    Error_Handler();
  }

  /** Configure Digital filter
  */
  if (HAL_I2CEx_ConfigDigitalFilter(&hi2c2, 0) != HAL_OK)
  {
    Error_Handler();
  }

}

static void MX_TIM14_Init(void)
{

  TIM_OC_InitTypeDef sConfigOC = {0};

  htim14.Instance = TIM14;
  htim14.Init.Prescaler = 0;
  htim14.Init.CounterMode = TIM_COUNTERMODE_UP;
  htim14.Init.Period = 65535;
  htim14.Init.ClockDivision = TIM_CLOCKDIVISION_DIV1;
  htim14.Init.AutoReloadPreload = TIM_AUTORELOAD_PRELOAD_DISABLE;
  if (HAL_TIM_Base_Init(&htim14) != HAL_OK)
  {
    Error_Handler();
  }
  if (HAL_TIM_PWM_Init(&htim14) != HAL_OK)
  {
    Error_Handler();
  }
  sConfigOC.OCMode = TIM_OCMODE_PWM1;
  sConfigOC.Pulse = 0;
  sConfigOC.OCPolarity = TIM_OCPOLARITY_HIGH;
  sConfigOC.OCFastMode = TIM_OCFAST_DISABLE;
  if (HAL_TIM_PWM_ConfigChannel(&htim14, &sConfigOC, TIM_CHANNEL_1) != HAL_OK)
  {
    Error_Handler();
  }
  /* USER CODE BEGIN TIM14_Init 2 */
  /* Reconfigure TIM14 as a 1us-resolution one-shot for the PA8 (Effect) falling-edge delay.
     CH1 (PA7) PWM is never started with HAL_TIM_PWM_Start, so CCER stays disabled, and PA7 is
     overridden to a GPIO output in main() anyway - running the counter therefore cannot disturb
     the PL9823 bit-banging. TIM14 CR1 has no OPM bit, so the ISR stops it.
     Priority 1: same as USART1/MIDI, above USART2 (2) and SysTick (3). */
  TIM14->CR1  &= ~TIM_CR1_CEN;
  TIM14->DIER &= ~TIM_DIER_UIE;
  TIM14->PSC   = (uint16_t)(48u - 1u);   /* TIM14CLK 48MHz / 48 = 1MHz */
  TIM14->ARR   = 65535u;
  TIM14->EGR   = TIM_EGR_UG;             /* load PSC/ARR immediately */
  TIM14->SR    = 0;
  HAL_NVIC_SetPriority(TIM14_IRQn, 1, 0);
  HAL_NVIC_EnableIRQ(TIM14_IRQn);
  /* USER CODE END TIM14_Init 2 */
  HAL_TIM_MspPostInit(&htim14);

}

static void MX_USART1_UART_Init(void)
{

  huart1.Instance = USART1;
  huart1.Init.BaudRate = 31250;
  huart1.Init.WordLength = UART_WORDLENGTH_8B;
  huart1.Init.StopBits = UART_STOPBITS_1;
  huart1.Init.Parity = UART_PARITY_NONE;
  huart1.Init.Mode = UART_MODE_TX_RX;
  huart1.Init.HwFlowCtl = UART_HWCONTROL_NONE;
  huart1.Init.OverSampling = UART_OVERSAMPLING_16;
  huart1.Init.OneBitSampling = UART_ONE_BIT_SAMPLE_DISABLE;
  huart1.AdvancedInit.AdvFeatureInit = UART_ADVFEATURE_NO_INIT;
  if (HAL_UART_Init(&huart1) != HAL_OK)
  {
    Error_Handler();
  }
  /* USER CODE BEGIN USART1_Init 2 */
  /* NVIC: not generated by CubeMX because it is missing from the .ioc; enabled by hand for interrupt-driven RX */
  HAL_NVIC_SetPriority(USART1_IRQn, 1, 0);
  HAL_NVIC_EnableIRQ(USART1_IRQn);
  /* USER CODE END USART1_Init 2 */

}

static void MX_USART2_UART_Init(void)
{

  huart2.Instance = USART2;
  huart2.Init.BaudRate = 115200;
  huart2.Init.WordLength = UART_WORDLENGTH_8B;
  huart2.Init.StopBits = UART_STOPBITS_1;
  huart2.Init.Parity = UART_PARITY_NONE;
  huart2.Init.Mode = UART_MODE_TX_RX;
  huart2.Init.HwFlowCtl = UART_HWCONTROL_NONE;
  huart2.Init.OverSampling = UART_OVERSAMPLING_16;
  huart2.Init.OneBitSampling = UART_ONE_BIT_SAMPLE_DISABLE;
  huart2.AdvancedInit.AdvFeatureInit = UART_ADVFEATURE_NO_INIT;
  if (HAL_UART_Init(&huart2) != HAL_OK)
  {
    Error_Handler();
  }
  /* USER CODE BEGIN USART2_Init 2 */
  /* J101 (STDC14) carries PA2=TX / PA3=RX, matching the default USART pins, so the code leaves
     UART_ADVFEATURE_SWAP_ENABLE unset. */
  /* NVIC: not generated by CubeMX because it is missing from the .ioc; enabled by hand for VCP debug console RX.
     Lower priority than MIDI (USART1=1). A raw RXNE interrupt, bypassing the HAL RX state machine */
  HAL_NVIC_SetPriority(USART2_IRQn, 2, 0);
  HAL_NVIC_EnableIRQ(USART2_IRQn);
  SET_BIT(USART2->CR1, USART_CR1_RXNEIE);
  /* USER CODE END USART2_Init 2 */

}

static void MX_GPIO_Init(void)
{
  GPIO_InitTypeDef GPIO_InitStruct = {0};

  /* GPIO Ports Clock Enable */
  __HAL_RCC_GPIOC_CLK_ENABLE();
  __HAL_RCC_GPIOF_CLK_ENABLE();
  __HAL_RCC_GPIOA_CLK_ENABLE();
  __HAL_RCC_GPIOB_CLK_ENABLE();

  /*Configure GPIO pin Output Level */
  HAL_GPIO_WritePin(GPIOC, GPIO_PIN_13|GPIO_PIN_14, GPIO_PIN_RESET);

  /*Configure GPIO pin Output Level */
  HAL_GPIO_WritePin(GPIOB, GPIO_PIN_12|GPIO_PIN_13|GPIO_PIN_14|GPIO_PIN_15
                          |GPIO_PIN_4|GPIO_PIN_5|GPIO_PIN_8|GPIO_PIN_9, GPIO_PIN_RESET);

  /*Configure GPIO pin Output Level */
  HAL_GPIO_WritePin(GPIOA, GPIO_PIN_8|GPIO_PIN_9|GPIO_PIN_10|GPIO_PIN_11, GPIO_PIN_RESET);

  /*Configure GPIO pins : PC13 PC14 */
  GPIO_InitStruct.Pin = GPIO_PIN_13|GPIO_PIN_14;
  GPIO_InitStruct.Mode = GPIO_MODE_OUTPUT_PP;
  GPIO_InitStruct.Pull = GPIO_NOPULL;
  GPIO_InitStruct.Speed = GPIO_SPEED_FREQ_LOW;
  HAL_GPIO_Init(GPIOC, &GPIO_InitStruct);

  /*Configure GPIO pin : PC15 */
  GPIO_InitStruct.Pin = GPIO_PIN_15;
  GPIO_InitStruct.Mode = GPIO_MODE_INPUT;
  GPIO_InitStruct.Pull = GPIO_NOPULL;
  HAL_GPIO_Init(GPIOC, &GPIO_InitStruct);

  /*Configure GPIO pins : PF0 PF1 */
  GPIO_InitStruct.Pin = GPIO_PIN_0|GPIO_PIN_1;
  GPIO_InitStruct.Mode = GPIO_MODE_INPUT;
  GPIO_InitStruct.Pull = GPIO_NOPULL;
  HAL_GPIO_Init(GPIOF, &GPIO_InitStruct);

  /*Configure GPIO pins : PA4 PA5 PA6 PA15 */
  GPIO_InitStruct.Pin = GPIO_PIN_4|GPIO_PIN_5|GPIO_PIN_6|GPIO_PIN_15;
  GPIO_InitStruct.Mode = GPIO_MODE_INPUT;
  GPIO_InitStruct.Pull = GPIO_PULLUP;
  HAL_GPIO_Init(GPIOA, &GPIO_InitStruct);

  /*Configure GPIO pins : PB0 PB1 PB2 PB10
                           PB11 PB3 */
  GPIO_InitStruct.Pin = GPIO_PIN_0|GPIO_PIN_1|GPIO_PIN_2|GPIO_PIN_10
                          |GPIO_PIN_11|GPIO_PIN_3;
  GPIO_InitStruct.Mode = GPIO_MODE_INPUT;
  GPIO_InitStruct.Pull = GPIO_NOPULL;
  HAL_GPIO_Init(GPIOB, &GPIO_InitStruct);

  /*Configure GPIO pins : PB12 PB13 PB14 PB15
                           PB4 PB5 PB8 PB9 */
  GPIO_InitStruct.Pin = GPIO_PIN_12|GPIO_PIN_13|GPIO_PIN_14|GPIO_PIN_15
                          |GPIO_PIN_4|GPIO_PIN_5|GPIO_PIN_8|GPIO_PIN_9;
  GPIO_InitStruct.Mode = GPIO_MODE_OUTPUT_PP;
  GPIO_InitStruct.Pull = GPIO_NOPULL;
  GPIO_InitStruct.Speed = GPIO_SPEED_FREQ_LOW;
  HAL_GPIO_Init(GPIOB, &GPIO_InitStruct);

  /*Configure GPIO pins : PA8 PA9 PA10 PA11 */
  GPIO_InitStruct.Pin = GPIO_PIN_8|GPIO_PIN_9|GPIO_PIN_10|GPIO_PIN_11;
  GPIO_InitStruct.Mode = GPIO_MODE_OUTPUT_PP;
  GPIO_InitStruct.Pull = GPIO_NOPULL;
  GPIO_InitStruct.Speed = GPIO_SPEED_FREQ_LOW;
  HAL_GPIO_Init(GPIOA, &GPIO_InitStruct);

  /*Configure GPIO pin : PA12 */
  GPIO_InitStruct.Pin = GPIO_PIN_12;
  GPIO_InitStruct.Mode = GPIO_MODE_INPUT;
  GPIO_InitStruct.Pull = GPIO_NOPULL;
  HAL_GPIO_Init(GPIOA, &GPIO_InitStruct);

}

/* USER CODE BEGIN 4 */

/* Overrun enabled: on an error such as ORE, re-arm reception so it does not stall.
   The occurrences are counted in midi_rx_err. ORE means one byte on the wire was missed,
   which makes it the primary health metric for sustained reception (reported by MSTAT). */
void HAL_UART_ErrorCallback(UART_HandleTypeDef *huart)
{
    if (huart->Instance == USART1) {
        midi_rx_err++;
        HAL_UART_Receive_IT(&huart1, (uint8_t *)&midi_rx_buf, 1);
    }
}

/* ===== Implementation summary =====
   Implemented:
     - Signal path (PA8/PA9), 3-step Bias (PA10/PA11), 3-state Input filter (PB12/PB13/PB14)
     - 3-state Response (PB4/PB15), read from PB0/PB1
     - Four LED indication sequences (Bias=orange / Response=cyan / Input=green / MIDI-Learn=white)
     - Footswitch, latch/momentary, DIP switches, MIDI-IN/Thru, MIDI-Learn, PowerGood ADC
     - MIDI Thru passes every byte straight through, including our own toggle CCs and incoming 0xFE.
       Store-and-forward was removed because it broke on interleaved input.
     - MIDI-OUT Active Sensing (0xFE) sent every 250ms
     - Toggle settings changeable over MIDI
         CC83=Input / CC84=Response / CC85=Bias; value split into four bands to select the state.
         Active channel: DIP-SW4 OFF = fixed CH12 / ON = the MIDI-Learn channel (same rule as on/off).
         Moving a physical toggle clears the override. Received CCs are serialized through a ring
         buffer (midi_evt_*) so bursts such as a preset recall are not dropped.
         The MRECV command injects MIDI-IN bytes for testing from the CLI.
   Not implemented:
     - Unsolicited MIDI-OUT transmission other than Active Sensing (trigger conditions undecided)
   Hardware notes:
     - PB15 is the Response Gradual output.
       The NJW4191 OSC pin is tied to GND, the correct configuration when no external clock is used.
     - PC14 drives the heartbeat LED D114. Up to v1.0 it also drove D115 in opposite phase through
       the 74HCT04 (4A->4Y); v1.1 removed D115 and reassigned the 74HCT04 gates (MIDI-OUT, PB5).
     - MIDI-OUT (v1.1): PB6 -> R123 -> U107 (1->2->3->4, non-inverting) -> D118 cathode, anode -> R128
       -> J104 Tip. The latch input PF0 reads the same Tip, and no hardware gate disables MIDI-OUT in
       latch mode, so Thru, Active Sensing and MSEND are all held off while DIP-SW3 is OFF.
       PB6 gets the internal pull-up in the USART1 MSP init (.ioc stays NOPULL; USER CODE overrides it).
       It is a safeguard for while TE=0 after that init; with TE=1 the USART drives PB6 High at idle.
       It cannot hold PB6 between reset and the MSP init; that needs an external pull-up (a candidate
       for a later board revision).
     - PB5 (through U107) switches three things together: U109 (latch Tip pull-up, R127 3k3 + R144 470),
       U110 (the MIDI-mode Ring current source, closed when PB5 is Low) and D110 (lit when PB5 is High).
*/

/* USER CODE END 4 */

void Error_Handler(void)
{
  __disable_irq();
  while (1)
  {
  }
}
